AUTOSAR XML (schema 4-2-2)
package /STELLANTIS/EPT/ASWCs
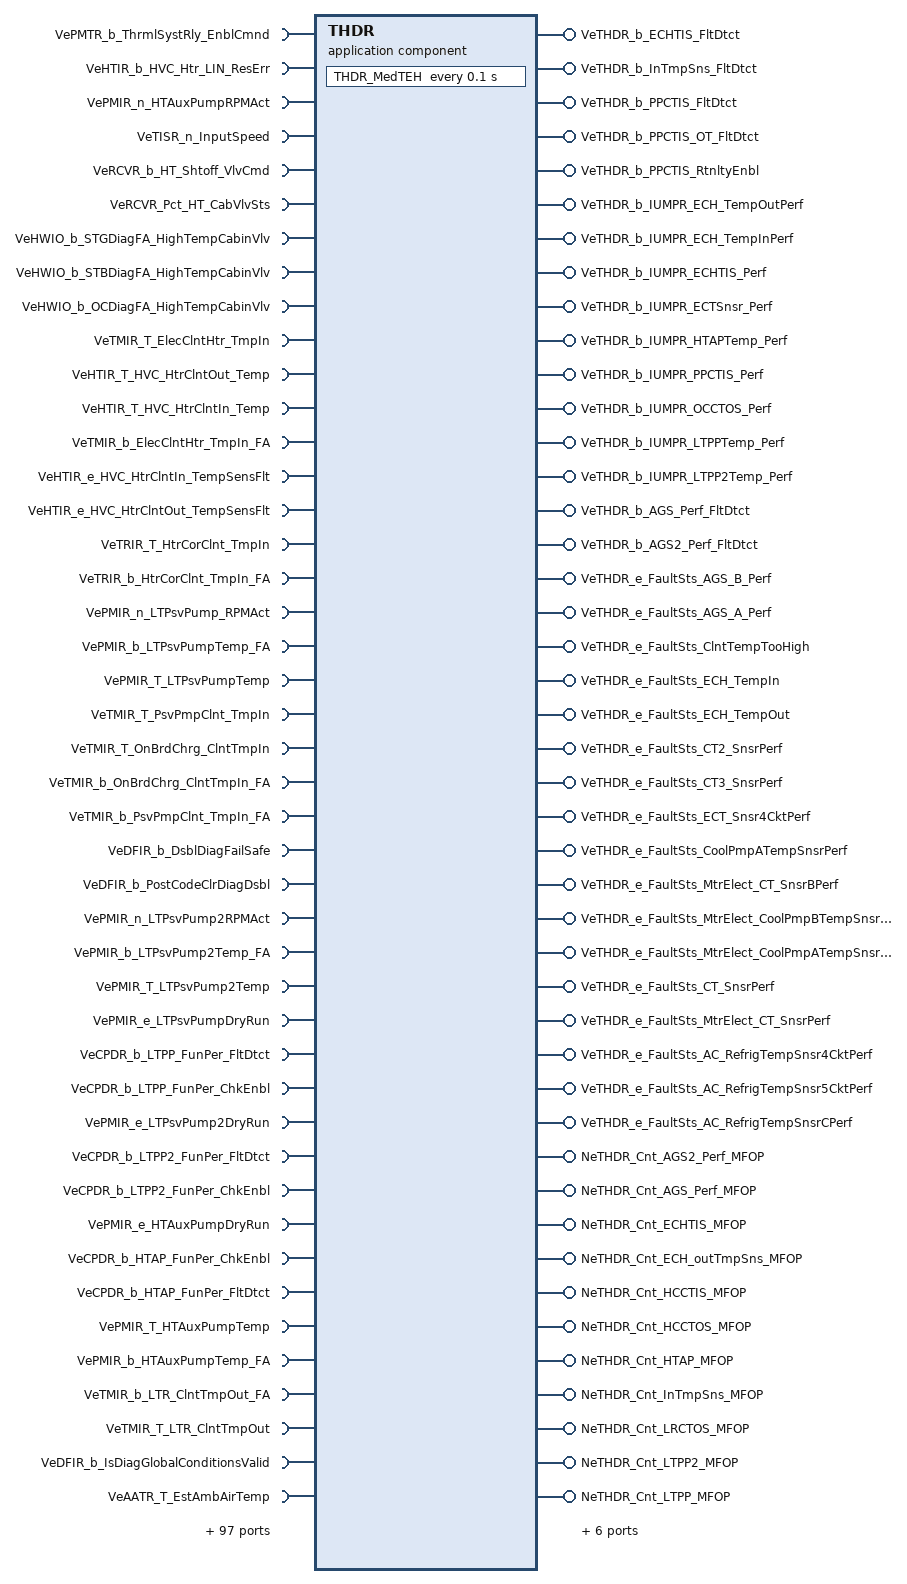
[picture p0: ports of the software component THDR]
  application sw component type THDR
    124 x require port:
      VePMTR_b_ThrmlSystRly_EnblCmnd: variation-point={short-label=vpVePMTR_b_ThrmlSystRly_EnblCmnd, sw-syscond=1}, nonqueued-receiver-com-spec{data-element=Value, init-value=0}, required-interface=VePMTR_b_ThrmlSystRly_EnblCmnd
      VeHTIR_b_HVC_Htr_LIN_ResErr: variation-point={short-label=vpVeHTIR_b_HVC_Htr_LIN_ResErr, sw-syscond=1}, nonqueued-receiver-com-spec{data-element=Value, init-value=0}, required-interface=VeHTIR_b_HVC_Htr_LIN_ResErr
      VePMIR_n_HTAuxPumpRPMAct: variation-point={short-label=vpVePMIR_n_HTAuxPumpRPMAct, sw-syscond=1}, nonqueued-receiver-com-spec{data-element=Value, init-value=0}, required-interface=VePMIR_n_HTAuxPumpRPMAct
      VeTISR_n_InputSpeed: variation-point={short-label=vpVeTISR_n_InputSpeed, sw-syscond=1}, nonqueued-receiver-com-spec{data-element=Value, init-value=0}, required-interface=VeTISR_n_InputSpeed
      VeRCVR_b_HT_Shtoff_VlvCmd: variation-point={short-label=vpVeRCVR_b_HT_Shtoff_VlvCmd, sw-syscond=1}, nonqueued-receiver-com-spec{data-element=Value, init-value=0}, required-interface=VeRCVR_b_HT_Shtoff_VlvCmd
      VeRCVR_Pct_HT_CabVlvSts: variation-point={short-label=vpVeRCVR_Pct_HT_CabVlvSts, sw-syscond=1}, nonqueued-receiver-com-spec{data-element=Value, init-value=0}, required-interface=VeRCVR_Pct_HT_CabVlvSts
      VeHWIO_b_STGDiagFA_HighTempCabinVlv: variation-point={short-label=vpVeHWIO_b_STGDiagFA_HighTempCabinVlv, sw-syscond=1}, nonqueued-receiver-com-spec{data-element=Value, init-value=0}, required-interface=VeHWIO_b_STGDiagFA_HighTempCabinVlv
      VeHWIO_b_STBDiagFA_HighTempCabinVlv: variation-point={short-label=vpVeHWIO_b_STBDiagFA_HighTempCabinVlv, sw-syscond=1}, nonqueued-receiver-com-spec{data-element=Value, init-value=0}, required-interface=VeHWIO_b_STBDiagFA_HighTempCabinVlv
      VeHWIO_b_OCDiagFA_HighTempCabinVlv: variation-point={short-label=vpVeHWIO_b_OCDiagFA_HighTempCabinVlv, sw-syscond=1}, nonqueued-receiver-com-spec{data-element=Value, init-value=0}, required-interface=VeHWIO_b_OCDiagFA_HighTempCabinVlv
      VeTMIR_T_ElecClntHtr_TmpIn: variation-point={short-label=vpVeTMIR_T_ElecClntHtr_TmpIn, sw-syscond=1}, nonqueued-receiver-com-spec{data-element=Value, init-value=0}, required-interface=VeTMIR_T_ElecClntHtr_TmpIn
      VeHTIR_T_HVC_HtrClntOut_Temp: variation-point={short-label=vpVeHTIR_T_HVC_HtrClntOut_Temp, sw-syscond=1}, nonqueued-receiver-com-spec{data-element=Value, init-value=0}, required-interface=VeHTIR_T_HVC_HtrClntOut_Temp
      VeHTIR_T_HVC_HtrClntIn_Temp: variation-point={short-label=vpVeHTIR_T_HVC_HtrClntIn_Temp, sw-syscond=1}, nonqueued-receiver-com-spec{data-element=Value, init-value=0}, required-interface=VeHTIR_T_HVC_HtrClntIn_Temp
      VeTMIR_b_ElecClntHtr_TmpIn_FA: variation-point={short-label=vpVeTMIR_b_ElecClntHtr_TmpIn_FA, sw-syscond=1}, nonqueued-receiver-com-spec{data-element=Value, init-value=0}, required-interface=VeTMIR_b_ElecClntHtr_TmpIn_FA
      VeHTIR_e_HVC_HtrClntIn_TempSensFlt: variation-point={short-label=vpVeHTIR_e_HVC_HtrClntIn_TempSensFlt, sw-syscond=1}, nonqueued-receiver-com-spec{data-element=Value, init-value=CeHTIR_e_Warning_False}, required-interface=VeHTIR_e_HVC_HtrClntIn_TempSensFlt
      VeHTIR_e_HVC_HtrClntOut_TempSensFlt: variation-point={short-label=vpVeHTIR_e_HVC_HtrClntOut_TempSensFlt, sw-syscond=1}, nonqueued-receiver-com-spec{data-element=Value, init-value=CeHTIR_e_Warning_False}, required-interface=VeHTIR_e_HVC_HtrClntOut_TempSensFlt
      VeTRIR_T_HtrCorClnt_TmpIn: variation-point={short-label=vpVeTRIR_T_HtrCorClnt_TmpIn, sw-syscond=1}, nonqueued-receiver-com-spec{data-element=Value, init-value=0}, required-interface=VeTRIR_T_HtrCorClnt_TmpIn
      VeTRIR_b_HtrCorClnt_TmpIn_FA: variation-point={short-label=vpVeTRIR_b_HtrCorClnt_TmpIn_FA, sw-syscond=1}, nonqueued-receiver-com-spec{data-element=Value, init-value=0}, required-interface=VeTRIR_b_HtrCorClnt_TmpIn_FA
      VePMIR_n_LTPsvPump_RPMAct: variation-point={short-label=vpVePMIR_n_LTPsvPump_RPMAct, sw-syscond=1}, nonqueued-receiver-com-spec{data-element=Value, init-value=0}, required-interface=VePMIR_n_LTPsvPump_RPMAct
      VePMIR_b_LTPsvPumpTemp_FA: variation-point={short-label=vpVePMIR_b_LTPsvPumpTemp_FA, sw-syscond=1}, nonqueued-receiver-com-spec{data-element=Value, init-value=0}, required-interface=VePMIR_b_LTPsvPumpTemp_FA
      VePMIR_T_LTPsvPumpTemp: variation-point={short-label=vpVePMIR_T_LTPsvPumpTemp, sw-syscond=1}, nonqueued-receiver-com-spec{data-element=Value, init-value=0}, required-interface=VePMIR_T_LTPsvPumpTemp
      VeTMIR_T_PsvPmpClnt_TmpIn: variation-point={short-label=vpVeTMIR_T_PsvPmpClnt_TmpIn, sw-syscond=1}, nonqueued-receiver-com-spec{data-element=Value, init-value=0}, required-interface=VeTMIR_T_PsvPmpClnt_TmpIn
      VeTMIR_T_OnBrdChrg_ClntTmpIn: variation-point={short-label=vpVeTMIR_T_OnBrdChrg_ClntTmpIn, sw-syscond=1}, nonqueued-receiver-com-spec{data-element=Value, init-value=0}, required-interface=VeTMIR_T_OnBrdChrg_ClntTmpIn
      VeTMIR_b_OnBrdChrg_ClntTmpIn_FA: variation-point={short-label=vpVeTMIR_b_OnBrdChrg_ClntTmpIn_FA, sw-syscond=1}, nonqueued-receiver-com-spec{data-element=Value, init-value=0}, required-interface=VeTMIR_b_OnBrdChrg_ClntTmpIn_FA
      VeTMIR_b_PsvPmpClnt_TmpIn_FA: variation-point={short-label=vpVeTMIR_b_PsvPmpClnt_TmpIn_FA, sw-syscond=1}, nonqueued-receiver-com-spec{data-element=Value, init-value=0}, required-interface=VeTMIR_b_PsvPmpClnt_TmpIn_FA
      VeDFIR_b_DsblDiagFailSafe: variation-point={short-label=vpVeDFIR_b_DsblDiagFailSafe, sw-syscond=1}, nonqueued-receiver-com-spec{data-element=Value, init-value=0}, required-interface=VeDFIR_b_DsblDiagFailSafe
      VeDFIR_b_PostCodeClrDiagDsbl: variation-point={short-label=vpVeDFIR_b_PostCodeClrDiagDsbl, sw-syscond=1}, nonqueued-receiver-com-spec{data-element=Value, init-value=0}, required-interface=VeDFIR_b_PostCodeClrDiagDsbl
      VePMIR_n_LTPsvPump2RPMAct: variation-point={short-label=vpVePMIR_n_LTPsvPump2RPMAct, sw-syscond=1}, nonqueued-receiver-com-spec{data-element=Value, init-value=0}, required-interface=VePMIR_n_LTPsvPump2RPMAct
      VePMIR_b_LTPsvPump2Temp_FA: variation-point={short-label=vpVePMIR_b_LTPsvPump2Temp_FA, sw-syscond=1}, nonqueued-receiver-com-spec{data-element=Value, init-value=0}, required-interface=VePMIR_b_LTPsvPump2Temp_FA
      VePMIR_T_LTPsvPump2Temp: variation-point={short-label=vpVePMIR_T_LTPsvPump2Temp, sw-syscond=1}, nonqueued-receiver-com-spec{data-element=Value, init-value=0}, required-interface=VePMIR_T_LTPsvPump2Temp
      VePMIR_e_LTPsvPumpDryRun: variation-point={short-label=vpVePMIR_e_LTPsvPumpDryRun, sw-syscond=1}, nonqueued-receiver-com-spec{data-element=Value, init-value=CePMPR_e_FTSNA_False}, required-interface=VePMIR_e_LTPsvPumpDryRun
      VeCPDR_b_LTPP_FunPer_FltDtct: variation-point={short-label=vpVeCPDR_b_LTPP_FunPer_FltDtct, sw-syscond=1}, nonqueued-receiver-com-spec{data-element=Value, init-value=0}, required-interface=VeCPDR_b_LTPP_FunPer_FltDtct
      VeCPDR_b_LTPP_FunPer_ChkEnbl: variation-point={short-label=vpVeCPDR_b_LTPP_FunPer_ChkEnbl, sw-syscond=1}, nonqueued-receiver-com-spec{data-element=Value, init-value=0}, required-interface=VeCPDR_b_LTPP_FunPer_ChkEnbl
      VePMIR_e_LTPsvPump2DryRun: variation-point={short-label=vpVePMIR_e_LTPsvPump2DryRun, sw-syscond=1}, nonqueued-receiver-com-spec{data-element=Value, init-value=CePMPR_e_FTSNA_False}, required-interface=VePMIR_e_LTPsvPump2DryRun
      VeCPDR_b_LTPP2_FunPer_FltDtct: variation-point={short-label=vpVeCPDR_b_LTPP2_FunPer_FltDtct, sw-syscond=1}, nonqueued-receiver-com-spec{data-element=Value, init-value=0}, required-interface=VeCPDR_b_LTPP2_FunPer_FltDtct
      VeCPDR_b_LTPP2_FunPer_ChkEnbl: variation-point={short-label=vpVeCPDR_b_LTPP2_FunPer_ChkEnbl, sw-syscond=1}, nonqueued-receiver-com-spec{data-element=Value, init-value=0}, required-interface=VeCPDR_b_LTPP2_FunPer_ChkEnbl
      VePMIR_e_HTAuxPumpDryRun: variation-point={short-label=vpVePMIR_e_HTAuxPumpDryRun, sw-syscond=1}, nonqueued-receiver-com-spec{data-element=Value, init-value=CePMPR_e_FTSNA_False}, required-interface=VePMIR_e_HTAuxPumpDryRun
      VeCPDR_b_HTAP_FunPer_ChkEnbl: variation-point={short-label=vpVeCPDR_b_HTAP_FunPer_ChkEnbl, sw-syscond=1}, nonqueued-receiver-com-spec{data-element=Value, init-value=0}, required-interface=VeCPDR_b_HTAP_FunPer_ChkEnbl
      VeCPDR_b_HTAP_FunPer_FltDtct: variation-point={short-label=vpVeCPDR_b_HTAP_FunPer_FltDtct, sw-syscond=1}, nonqueued-receiver-com-spec{data-element=Value, init-value=0}, required-interface=VeCPDR_b_HTAP_FunPer_FltDtct
      VePMIR_T_HTAuxPumpTemp: variation-point={short-label=vpVePMIR_T_HTAuxPumpTemp, sw-syscond=1}, nonqueued-receiver-com-spec{data-element=Value, init-value=0}, required-interface=VePMIR_T_HTAuxPumpTemp
      VePMIR_b_HTAuxPumpTemp_FA: variation-point={short-label=vpVePMIR_b_HTAuxPumpTemp_FA, sw-syscond=1}, nonqueued-receiver-com-spec{data-element=Value, init-value=0}, required-interface=VePMIR_b_HTAuxPumpTemp_FA
      VeTMIR_b_LTR_ClntTmpOut_FA: variation-point={short-label=vpVeTMIR_b_LTR_ClntTmpOut_FA, sw-syscond=1}, nonqueued-receiver-com-spec{data-element=Value, init-value=0}, required-interface=VeTMIR_b_LTR_ClntTmpOut_FA
      VeTMIR_T_LTR_ClntTmpOut: variation-point={short-label=vpVeTMIR_T_LTR_ClntTmpOut, sw-syscond=1}, nonqueued-receiver-com-spec{data-element=Value, init-value=0}, required-interface=VeTMIR_T_LTR_ClntTmpOut
      VeDFIR_b_IsDiagGlobalConditionsValid: variation-point={short-label=vpVeDFIR_b_IsDiagGlobalConditionsValid, sw-syscond=1}, nonqueued-receiver-com-spec{data-element=Value, init-value=0}, required-interface=VeDFIR_b_IsDiagGlobalConditionsValid
      VeAATR_T_EstAmbAirTemp: variation-point={short-label=vpVeAATR_T_EstAmbAirTemp, sw-syscond=1}, nonqueued-receiver-com-spec{data-element=Value, init-value=0}, required-interface=VeAATR_T_EstAmbAirTemp
      VePMDR_e_PMM_PowerMode: variation-point={short-label=vpVePMDR_e_PMM_PowerMode, sw-syscond=1}, nonqueued-receiver-com-spec{data-element=Value, init-value=CePMDR_e_PowerMode_Off}, required-interface=VePMDR_e_PMM_PowerMode
      VeTAIR_Pct_HTL_BypsVlv_ActlPstn: variation-point={short-label=vpVeTAIR_Pct_HTL_BypsVlv_ActlPstn, sw-syscond=1}, nonqueued-receiver-com-spec{data-element=Value, init-value=0}, required-interface=VeTAIR_Pct_HTL_BypsVlv_ActlPstn
      VeTAIR_e_AGS_CalibrationSts: variation-point={short-label=vpVeTAIR_e_AGS_CalibrationSts, sw-syscond=1}, nonqueued-receiver-com-spec{data-element=Value, init-value=CeTAIR_e_AGS_NotCalibrated}, required-interface=VeTAIR_e_AGS_CalibrationSts
      VeFSCR_b_AGS_CalAtmptThrshold: variation-point={short-label=vpVeFSCR_b_AGS_CalAtmptThrshold, sw-syscond=1}, nonqueued-receiver-com-spec{data-element=Value, init-value=0}, required-interface=VeFSCR_b_AGS_CalAtmptThrshold
      VeFSCR_e_AGS_PosReq: variation-point={short-label=vpVeFSCR_e_AGS_PosReq, sw-syscond=1}, nonqueued-receiver-com-spec{data-element=Value, init-value=CeFSCR_e_Open100}, required-interface=VeFSCR_e_AGS_PosReq
      VeTAIR_e_AGS_CurrPos: variation-point={short-label=vpVeTAIR_e_AGS_CurrPos, sw-syscond=1}, nonqueued-receiver-com-spec{data-element=Value, init-value=CeFSCR_e_Open100}, required-interface=VeTAIR_e_AGS_CurrPos
      VeTAIR_b_AGS_CurrPosFA: variation-point={short-label=vpVeTAIR_b_AGS_CurrPosFA, sw-syscond=1}, nonqueued-receiver-com-spec{data-element=Value, init-value=0}, required-interface=VeTAIR_b_AGS_CurrPosFA
      VePMIR_I_HTAuxPumpCurrent: variation-point={short-label=vpVePMIR_I_HTAuxPumpCurrent, sw-syscond=1}, nonqueued-receiver-com-spec{data-element=Value, init-value=0}, required-interface=VePMIR_I_HTAuxPumpCurrent
      VeDMAB_y_StatusByte_LIN2_BusOff: nonqueued-receiver-com-spec{data-element=Value, init-value=0}, required-interface=VeDMAB_y_StatusByte_LIN2_BusOff
      VeDMAB_y_StatusByte_LostComm_AGS_B: nonqueued-receiver-com-spec{data-element=Value, init-value=0}, required-interface=VeDMAB_y_StatusByte_LostComm_AGS_B
      VeDMAB_y_StatusByte_LIN3_BusOff: nonqueued-receiver-com-spec{data-element=Value, init-value=0}, required-interface=VeDMAB_y_StatusByte_LIN3_BusOff
      VeDMAB_y_StatusByte_LostComm_AGS_A: nonqueued-receiver-com-spec{data-element=Value, init-value=0}, required-interface=VeDMAB_y_StatusByte_LostComm_AGS_A
      VeDMAB_y_StatusByte_ThrmlRlyCtrlCkt: nonqueued-receiver-com-spec{data-element=Value, init-value=0}, required-interface=VeDMAB_y_StatusByte_ThrmlRlyCtrlCkt
      VeDMAB_y_StatusByte_CoolPmpACtrlCktPerf: nonqueued-receiver-com-spec{data-element=Value, init-value=0}, required-interface=VeDMAB_y_StatusByte_CoolPmpACtrlCktPerf
      VeDMAB_y_StatusByte_CoolPmpATempSnsrPerf: nonqueued-receiver-com-spec{data-element=Value, init-value=0}, required-interface=VeDMAB_y_StatusByte_CoolPmpATempSnsrPerf
      VeDMAB_y_StatusByte_ECH_TempIn: nonqueued-receiver-com-spec{data-element=Value, init-value=0}, required-interface=VeDMAB_y_StatusByte_ECH_TempIn
      VeDMAB_y_StatusByte_ECH_TempOut: nonqueued-receiver-com-spec{data-element=Value, init-value=0}, required-interface=VeDMAB_y_StatusByte_ECH_TempOut
      VeDMAB_y_StatusByte_LIN1_BusOff: nonqueued-receiver-com-spec{data-element=Value, init-value=0}, required-interface=VeDMAB_y_StatusByte_LIN1_BusOff
      VeDMAB_y_StatusByte_CT2_SnsrCktHi: nonqueued-receiver-com-spec{data-element=Value, init-value=0}, required-interface=VeDMAB_y_StatusByte_CT2_SnsrCktHi
      VeDMAB_y_StatusByte_CT2_SnsrCktLo: nonqueued-receiver-com-spec{data-element=Value, init-value=0}, required-interface=VeDMAB_y_StatusByte_CT2_SnsrCktLo
      VeDMAB_y_StatusByte_CT2_SnsrPerf: nonqueued-receiver-com-spec{data-element=Value, init-value=0}, required-interface=VeDMAB_y_StatusByte_CT2_SnsrPerf
      VeDMAB_y_StatusByte_LostCommCoolHtrA: nonqueued-receiver-com-spec{data-element=Value, init-value=0}, required-interface=VeDMAB_y_StatusByte_LostCommCoolHtrA
      VeDMAB_y_StatusByte_CT3_SnsrPerf: nonqueued-receiver-com-spec{data-element=Value, init-value=0}, required-interface=VeDMAB_y_StatusByte_CT3_SnsrPerf
      VeDMAB_y_StatusByte_LostCommCoolPmpA: nonqueued-receiver-com-spec{data-element=Value, init-value=0}, required-interface=VeDMAB_y_StatusByte_LostCommCoolPmpA
      VeDMAB_y_StatusByte_CT_SnsrPerf: nonqueued-receiver-com-spec{data-element=Value, init-value=0}, required-interface=VeDMAB_y_StatusByte_CT_SnsrPerf
      VeDMAB_y_StatusByte_MtrElect_CooPumBOvrSpd: nonqueued-receiver-com-spec{data-element=Value, init-value=0}, required-interface=VeDMAB_y_StatusByte_MtrElect_CooPumBOvrSpd
      VeDMAB_y_StatusByte_MtrElect_CoolPmpATempSnsrPerf: nonqueued-receiver-com-spec{data-element=Value, init-value=0}, required-interface=VeDMAB_y_StatusByte_MtrElect_CoolPmpATempSnsrPerf
      VeDMAB_y_StatusByte_MtrElect_CoolPmpBTempSnsrPerf: nonqueued-receiver-com-spec{data-element=Value, init-value=0}, required-interface=VeDMAB_y_StatusByte_MtrElect_CoolPmpBTempSnsrPerf
      VeDMAB_y_StatusByte_MtrElect_CoolPumAOvrSpd: nonqueued-receiver-com-spec{data-element=Value, init-value=0}, required-interface=VeDMAB_y_StatusByte_MtrElect_CoolPumAOvrSpd
      VeDMAB_y_StatusByte_MtrElect_CoolPumBCtrlPerf: nonqueued-receiver-com-spec{data-element=Value, init-value=0}, required-interface=VeDMAB_y_StatusByte_MtrElect_CoolPumBCtrlPerf
      VeDMAB_y_StatusByte_PwrElecPmpPerf: nonqueued-receiver-com-spec{data-element=Value, init-value=0}, required-interface=VeDMAB_y_StatusByte_PwrElecPmpPerf
      VeDMAB_y_StatusByte_CommBusOff: nonqueued-receiver-com-spec{data-element=Value, init-value=0}, required-interface=VeDMAB_y_StatusByte_CommBusOff
      VeDMAB_y_StatusByte_LosCommBECM_A: nonqueued-receiver-com-spec{data-element=Value, init-value=0}, required-interface=VeDMAB_y_StatusByte_LosCommBECM_A
      VeDMAB_y_StatusByte_MtrElect_CT_SnsrPerf: nonqueued-receiver-com-spec{data-element=Value, init-value=0}, required-interface=VeDMAB_y_StatusByte_MtrElect_CT_SnsrPerf
      VeDMAB_y_StatusByte_CT3_SnsrCktHi: nonqueued-receiver-com-spec{data-element=Value, init-value=0}, required-interface=VeDMAB_y_StatusByte_CT3_SnsrCktHi
      VeDMAB_y_StatusByte_CT3_SnsrCktLo: nonqueued-receiver-com-spec{data-element=Value, init-value=0}, required-interface=VeDMAB_y_StatusByte_CT3_SnsrCktLo
      VeDMAB_y_StatusByte_CT_SnsrCktHi: nonqueued-receiver-com-spec{data-element=Value, init-value=0}, required-interface=VeDMAB_y_StatusByte_CT_SnsrCktHi
      VeDMAB_y_StatusByte_CT_SnsrCktLo: nonqueued-receiver-com-spec{data-element=Value, init-value=0}, required-interface=VeDMAB_y_StatusByte_CT_SnsrCktLo
      VeDMAB_y_StatusByte_MtrElect_CT2_SnsrBCktHi: nonqueued-receiver-com-spec{data-element=Value, init-value=0}, required-interface=VeDMAB_y_StatusByte_MtrElect_CT2_SnsrBCktHi
      VeDMAB_y_StatusByte_MtrElect_CT2_SnsrBCktLo: nonqueued-receiver-com-spec{data-element=Value, init-value=0}, required-interface=VeDMAB_y_StatusByte_MtrElect_CT2_SnsrBCktLo
      VeDMAB_y_StatusByte_MtrElect_CT_SnsrCktHi: nonqueued-receiver-com-spec{data-element=Value, init-value=0}, required-interface=VeDMAB_y_StatusByte_MtrElect_CT_SnsrCktHi
      VeDMAB_y_StatusByte_MtrElect_CT_SnsrCktLo: nonqueued-receiver-com-spec{data-element=Value, init-value=0}, required-interface=VeDMAB_y_StatusByte_MtrElect_CT_SnsrCktLo
      VeDMAB_y_StatusByte_CoolantVlvA_Perf: nonqueued-receiver-com-spec{data-element=Value, init-value=0}, required-interface=VeDMAB_y_StatusByte_CoolantVlvA_Perf
      VeDMAB_y_StatusByte_ECT_Snsr4CktPerf: nonqueued-receiver-com-spec{data-element=Value, init-value=0}, required-interface=VeDMAB_y_StatusByte_ECT_Snsr4CktPerf
      VeDMAB_y_StatusByte_LostCommMtrElectCoolPmpA: nonqueued-receiver-com-spec{data-element=Value, init-value=0}, required-interface=VeDMAB_y_StatusByte_LostCommMtrElectCoolPmpA
      VeDMAB_y_StatusByte_LostCommMtrElectCoolPmpB: nonqueued-receiver-com-spec{data-element=Value, init-value=0}, required-interface=VeDMAB_y_StatusByte_LostCommMtrElectCoolPmpB
      VeDMAB_y_StatusByte_MtrElect_CT_SnsrBPerf: nonqueued-receiver-com-spec{data-element=Value, init-value=0}, required-interface=VeDMAB_y_StatusByte_MtrElect_CT_SnsrBPerf
      VeDMAB_y_StatusByte_HB_PSC_CtrlValBCktPerf: nonqueued-receiver-com-spec{data-element=Value, init-value=0}, required-interface=VeDMAB_y_StatusByte_HB_PSC_CtrlValBCktPerf
      VeDMAB_y_StatusByte_LostCommHB_PSCCooCtrlVlvB: nonqueued-receiver-com-spec{data-element=Value, init-value=0}, required-interface=VeDMAB_y_StatusByte_LostCommHB_PSCCooCtrlVlvB
      VeTAIR_b_OEXV_RefTemp_FA: variation-point={short-label=vpVeTAIR_b_OEXV_RefTemp_FA, sw-syscond=1}, nonqueued-receiver-com-spec{data-element=Value, init-value=0}, required-interface=VeTAIR_b_OEXV_RefTemp_FA
      VeTAIR_b_OEXV_InTempSens_FA: variation-point={short-label=vpVeTAIR_b_OEXV_InTempSens_FA, sw-syscond=1}, nonqueued-receiver-com-spec{data-element=Value, init-value=0}, required-interface=VeTAIR_b_OEXV_InTempSens_FA
      VeTAIR_b_EEXV_RefTemp_FA: variation-point={short-label=vpVeTAIR_b_EEXV_RefTemp_FA, sw-syscond=1}, nonqueued-receiver-com-spec{data-element=Value, init-value=0}, required-interface=VeTAIR_b_EEXV_RefTemp_FA
      VeTAIR_T_OEXV_RefTemp: variation-point={short-label=vpVeTAIR_T_OEXV_RefTemp, sw-syscond=1}, nonqueued-receiver-com-spec{data-element=Value, init-value=0}, required-interface=VeTAIR_T_OEXV_RefTemp
      VeTAIR_T_OEXV_InTempSens: variation-point={short-label=vpVeTAIR_T_OEXV_InTempSens, sw-syscond=1}, nonqueued-receiver-com-spec{data-element=Value, init-value=0}, required-interface=VeTAIR_T_OEXV_InTempSens
      VeTAIR_T_EEXV_RefTemp: variation-point={short-label=vpVeTAIR_T_EEXV_RefTemp, sw-syscond=1}, nonqueued-receiver-com-spec{data-element=Value, init-value=0}, required-interface=VeTAIR_T_EEXV_RefTemp
      VeTAIR_e_CompStat: variation-point={short-label=vpVeTAIR_e_CompStat, sw-syscond=1}, nonqueued-receiver-com-spec{data-element=Value, init-value=CeTAIR_e_NormalOp}, required-interface=VeTAIR_e_CompStat
      VeTAIR_b_WinshldDfrst: variation-point={short-label=vpVeTAIR_b_WinshldDfrst, sw-syscond=1}, nonqueued-receiver-com-spec{data-element=Value, init-value=0}, required-interface=VeTAIR_b_WinshldDfrst
      VePLTR_t_HCPOffTime: variation-point={short-label=vpVePLTR_t_HCPOffTime, sw-syscond=1}, nonqueued-receiver-com-spec{data-element=Value, init-value=0}, required-interface=VePLTR_t_HCPOffTime
      VePLTR_b_HCPOffTimeFA: variation-point={short-label=vpVePLTR_b_HCPOffTimeFA, sw-syscond=1}, nonqueued-receiver-com-spec{data-element=Value, init-value=0}, required-interface=VePLTR_b_HCPOffTimeFA
      VeTAIR_n_CompSpdFdb: variation-point={short-label=vpVeTAIR_n_CompSpdFdb, sw-syscond=1}, nonqueued-receiver-com-spec{data-element=Value, init-value=0}, required-interface=VeTAIR_n_CompSpdFdb
      VeDMAB_y_StatusByte_EACPerf: nonqueued-receiver-com-spec{data-element=Value, init-value=0}, required-interface=VeDMAB_y_StatusByte_EACPerf
      VeDMAB_y_StatusByte_LostCommEAC: nonqueued-receiver-com-spec{data-element=Value, init-value=0}, required-interface=VeDMAB_y_StatusByte_LostCommEAC
      VeDMAB_y_StatusByte_AC_RefrigExpVlvAct_C_CntrlCktPerf: nonqueued-receiver-com-spec{data-element=Value, init-value=0}, required-interface=VeDMAB_y_StatusByte_AC_RefrigExpVlvAct_C_CntrlCktPerf
      VeDMAB_y_StatusByte_AC_RefrigTempSnsrCCkt: nonqueued-receiver-com-spec{data-element=Value, init-value=0}, required-interface=VeDMAB_y_StatusByte_AC_RefrigTempSnsrCCkt
      VeDMAB_y_StatusByte_LostCommACRefrigExpVlvActC: nonqueued-receiver-com-spec{data-element=Value, init-value=0}, required-interface=VeDMAB_y_StatusByte_LostCommACRefrigExpVlvActC
      VeDMAB_y_StatusByte_AC_RefrigTempSnsr5CktShotoBat: nonqueued-receiver-com-spec{data-element=Value, init-value=0}, required-interface=VeDMAB_y_StatusByte_AC_RefrigTempSnsr5CktShotoBat
      VeDMAB_y_StatusByte_AC_RefrigTempSnsr5CktShotoGro: nonqueued-receiver-com-spec{data-element=Value, init-value=0}, required-interface=VeDMAB_y_StatusByte_AC_RefrigTempSnsr5CktShotoGro
      VeDMAB_y_StatusByte_AC_RefrigExpVlvActD_CntrlCktPerf: nonqueued-receiver-com-spec{data-element=Value, init-value=0}, required-interface=VeDMAB_y_StatusByte_AC_RefrigExpVlvActD_CntrlCktPerf
      VeDMAB_y_StatusByte_AC_RefrigTempSnsrDCkt: nonqueued-receiver-com-spec{data-element=Value, init-value=0}, required-interface=VeDMAB_y_StatusByte_AC_RefrigTempSnsrDCkt
      VeDMAB_y_StatusByte_LostCommACRefrigExpVlvActD: nonqueued-receiver-com-spec{data-element=Value, init-value=0}, required-interface=VeDMAB_y_StatusByte_LostCommACRefrigExpVlvActD
      VeDMAB_y_StatusByte_AC_RefrigTempSnsr4CktPerf: nonqueued-receiver-com-spec{data-element=Value, init-value=0}, required-interface=VeDMAB_y_StatusByte_AC_RefrigTempSnsr4CktPerf
      VeDMAB_y_StatusByte_AC_RefrigTempSnsr5CktPerf: nonqueued-receiver-com-spec{data-element=Value, init-value=0}, required-interface=VeDMAB_y_StatusByte_AC_RefrigTempSnsr5CktPerf
      VeDMAB_y_StatusByte_AC_RefrigTempSnsrCPerf: nonqueued-receiver-com-spec{data-element=Value, init-value=0}, required-interface=VeDMAB_y_StatusByte_AC_RefrigTempSnsrCPerf
      VeDMAB_y_StatusByte_ClntTempTooHigh: nonqueued-receiver-com-spec{data-element=Value, init-value=0}, required-interface=VeDMAB_y_StatusByte_ClntTempTooHigh
      VeDMAB_y_StatusByte_AGS_A_Perf: nonqueued-receiver-com-spec{data-element=Value, init-value=0}, required-interface=VeDMAB_y_StatusByte_AGS_A_Perf
      VeDMAB_y_StatusByte_AGS_B_Perf: nonqueued-receiver-com-spec{data-element=Value, init-value=0}, required-interface=VeDMAB_y_StatusByte_AGS_B_Perf
      VeTAIR_Pct_CPV2_PstnAct: variation-point={short-label=vpVeTAIR_Pct_CPV2_PstnAct, sw-syscond=1}, nonqueued-receiver-com-spec{data-element=Value, init-value=0}, required-interface=VeTAIR_Pct_CPV2_PstnAct
      VeTAIR_b_CPV2_PstnAct_FA: variation-point={short-label=vpVeTAIR_b_CPV2_PstnAct_FA, sw-syscond=1}, nonqueued-receiver-com-spec{data-element=Value, init-value=0}, required-interface=VeTAIR_b_CPV2_PstnAct_FA
      VeDMAB_y_StatusByte_LostComm_HybPropSysCoolCntrlVal_E: nonqueued-receiver-com-spec{data-element=Value, init-value=0}, required-interface=VeDMAB_y_StatusByte_LostComm_HybPropSysCoolCntrlVal_E
      VeDMAB_y_StatusByte_HybPropSysCoolCntrlVal_E_Perf: nonqueued-receiver-com-spec{data-element=Value, init-value=0}, required-interface=VeDMAB_y_StatusByte_HybPropSysCoolCntrlVal_E_Perf
    33 x provide port:
      VeTHDR_b_ECHTIS_FltDtct: nonqueued-sender-com-spec{data-element=Value, init-value=0}, provided-interface=VeTHDR_b_ECHTIS_FltDtct
      VeTHDR_b_InTmpSns_FltDtct: nonqueued-sender-com-spec{data-element=Value, init-value=0}, provided-interface=VeTHDR_b_InTmpSns_FltDtct
      VeTHDR_b_PPCTIS_FltDtct: nonqueued-sender-com-spec{data-element=Value, init-value=0}, provided-interface=VeTHDR_b_PPCTIS_FltDtct
      VeTHDR_b_PPCTIS_OT_FltDtct: nonqueued-sender-com-spec{data-element=Value, init-value=0}, provided-interface=VeTHDR_b_PPCTIS_OT_FltDtct
      VeTHDR_b_PPCTIS_RtnltyEnbl: nonqueued-sender-com-spec{data-element=Value, init-value=0}, provided-interface=VeTHDR_b_PPCTIS_RtnltyEnbl
      VeTHDR_b_IUMPR_ECH_TempOutPerf: nonqueued-sender-com-spec{data-element=Value, init-value=0}, provided-interface=VeTHDR_b_IUMPR_ECH_TempOutPerf
      VeTHDR_b_IUMPR_ECH_TempInPerf: nonqueued-sender-com-spec{data-element=Value, init-value=0}, provided-interface=VeTHDR_b_IUMPR_ECH_TempInPerf
      VeTHDR_b_IUMPR_ECHTIS_Perf: nonqueued-sender-com-spec{data-element=Value, init-value=0}, provided-interface=VeTHDR_b_IUMPR_ECHTIS_Perf
      VeTHDR_b_IUMPR_ECTSnsr_Perf: nonqueued-sender-com-spec{data-element=Value, init-value=0}, provided-interface=VeTHDR_b_IUMPR_ECTSnsr_Perf
      VeTHDR_b_IUMPR_HTAPTemp_Perf: nonqueued-sender-com-spec{data-element=Value, init-value=0}, provided-interface=VeTHDR_b_IUMPR_HTAPTemp_Perf
      VeTHDR_b_IUMPR_PPCTIS_Perf: nonqueued-sender-com-spec{data-element=Value, init-value=0}, provided-interface=VeTHDR_b_IUMPR_PPCTIS_Perf
      VeTHDR_b_IUMPR_OCCTOS_Perf: nonqueued-sender-com-spec{data-element=Value, init-value=0}, provided-interface=VeTHDR_b_IUMPR_OCCTOS_Perf
      VeTHDR_b_IUMPR_LTPPTemp_Perf: nonqueued-sender-com-spec{data-element=Value, init-value=0}, provided-interface=VeTHDR_b_IUMPR_LTPPTemp_Perf
      VeTHDR_b_IUMPR_LTPP2Temp_Perf: nonqueued-sender-com-spec{data-element=Value, init-value=0}, provided-interface=VeTHDR_b_IUMPR_LTPP2Temp_Perf
      VeTHDR_b_AGS_Perf_FltDtct: nonqueued-sender-com-spec{data-element=Value, init-value=0}, provided-interface=VeTHDR_b_AGS_Perf_FltDtct
      VeTHDR_b_AGS2_Perf_FltDtct: nonqueued-sender-com-spec{data-element=Value, init-value=0}, provided-interface=VeTHDR_b_AGS2_Perf_FltDtct
      VeTHDR_e_FaultSts_AGS_B_Perf: nonqueued-sender-com-spec{data-element=Value, init-value=CeDFIB_e_Init}, provided-interface=VeTHDR_e_FaultSts_AGS_B_Perf
      VeTHDR_e_FaultSts_AGS_A_Perf: nonqueued-sender-com-spec{data-element=Value, init-value=CeDFIB_e_Init}, provided-interface=VeTHDR_e_FaultSts_AGS_A_Perf
      VeTHDR_e_FaultSts_ClntTempTooHigh: nonqueued-sender-com-spec{data-element=Value, init-value=CeDFIB_e_Init}, provided-interface=VeTHDR_e_FaultSts_ClntTempTooHigh
      VeTHDR_e_FaultSts_ECH_TempIn: nonqueued-sender-com-spec{data-element=Value, init-value=CeDFIB_e_Init}, provided-interface=VeTHDR_e_FaultSts_ECH_TempIn
      VeTHDR_e_FaultSts_ECH_TempOut: nonqueued-sender-com-spec{data-element=Value, init-value=CeDFIB_e_Init}, provided-interface=VeTHDR_e_FaultSts_ECH_TempOut
      VeTHDR_e_FaultSts_CT2_SnsrPerf: nonqueued-sender-com-spec{data-element=Value, init-value=CeDFIB_e_Init}, provided-interface=VeTHDR_e_FaultSts_CT2_SnsrPerf
      VeTHDR_e_FaultSts_CT3_SnsrPerf: nonqueued-sender-com-spec{data-element=Value, init-value=CeDFIB_e_Init}, provided-interface=VeTHDR_e_FaultSts_CT3_SnsrPerf
      VeTHDR_e_FaultSts_ECT_Snsr4CktPerf: nonqueued-sender-com-spec{data-element=Value, init-value=CeDFIB_e_Init}, provided-interface=VeTHDR_e_FaultSts_ECT_Snsr4CktPerf
      VeTHDR_e_FaultSts_CoolPmpATempSnsrPerf: nonqueued-sender-com-spec{data-element=Value, init-value=CeDFIB_e_Init}, provided-interface=VeTHDR_e_FaultSts_CoolPmpATempSnsrPerf
      VeTHDR_e_FaultSts_MtrElect_CT_SnsrBPerf: nonqueued-sender-com-spec{data-element=Value, init-value=CeDFIB_e_Init}, provided-interface=VeTHDR_e_FaultSts_MtrElect_CT_SnsrBPerf
      VeTHDR_e_FaultSts_MtrElect_CoolPmpBTempSnsrPerf: nonqueued-sender-com-spec{data-element=Value, init-value=CeDFIB_e_Init}, provided-interface=VeTHDR_e_FaultSts_MtrElect_CoolPmpBTempSnsrPerf
      VeTHDR_e_FaultSts_MtrElect_CoolPmpATempSnsrPerf: nonqueued-sender-com-spec{data-element=Value, init-value=CeDFIB_e_Init}, provided-interface=VeTHDR_e_FaultSts_MtrElect_CoolPmpATempSnsrPerf
      VeTHDR_e_FaultSts_CT_SnsrPerf: nonqueued-sender-com-spec{data-element=Value, init-value=CeDFIB_e_Init}, provided-interface=VeTHDR_e_FaultSts_CT_SnsrPerf
      VeTHDR_e_FaultSts_MtrElect_CT_SnsrPerf: nonqueued-sender-com-spec{data-element=Value, init-value=CeDFIB_e_Init}, provided-interface=VeTHDR_e_FaultSts_MtrElect_CT_SnsrPerf
      VeTHDR_e_FaultSts_AC_RefrigTempSnsr4CktPerf: nonqueued-sender-com-spec{data-element=Value, init-value=CeDFIB_e_Init}, provided-interface=VeTHDR_e_FaultSts_AC_RefrigTempSnsr4CktPerf
      VeTHDR_e_FaultSts_AC_RefrigTempSnsr5CktPerf: nonqueued-sender-com-spec{data-element=Value, init-value=CeDFIB_e_Init}, provided-interface=VeTHDR_e_FaultSts_AC_RefrigTempSnsr5CktPerf
      VeTHDR_e_FaultSts_AC_RefrigTempSnsrCPerf: nonqueued-sender-com-spec{data-element=Value, init-value=CeDFIB_e_Init}, provided-interface=VeTHDR_e_FaultSts_AC_RefrigTempSnsrCPerf
    17 x require port:
      NeTHDR_Cnt_AGS2_Perf_MFOP_Rx: nv-require-com-spec{init-value=0, variable=NeTHDR_Cnt_AGS2_Perf_MFOP}, required-interface=NeTHDR_Cnt_AGS2_Perf_MFOP
      NeTHDR_Cnt_AGS_Perf_MFOP_Rx: nv-require-com-spec{init-value=0, variable=NeTHDR_Cnt_AGS_Perf_MFOP}, required-interface=NeTHDR_Cnt_AGS_Perf_MFOP
      NeTHDR_Cnt_ECHTIS_MFOP_Rx: nv-require-com-spec{init-value=0, variable=NeTHDR_Cnt_ECHTIS_MFOP}, required-interface=NeTHDR_Cnt_ECHTIS_MFOP
      NeTHDR_Cnt_ECH_outTmpSns_MFOP_Rx: nv-require-com-spec{init-value=0, variable=NeTHDR_Cnt_ECH_outTmpSns_MFOP}, required-interface=NeTHDR_Cnt_ECH_outTmpSns_MFOP
      NeTHDR_Cnt_HCCTIS_MFOP_Rx: nv-require-com-spec{init-value=0, variable=NeTHDR_Cnt_HCCTIS_MFOP}, required-interface=NeTHDR_Cnt_HCCTIS_MFOP
      NeTHDR_Cnt_HCCTOS_MFOP_Rx: nv-require-com-spec{init-value=0, variable=NeTHDR_Cnt_HCCTOS_MFOP}, required-interface=NeTHDR_Cnt_HCCTOS_MFOP
      NeTHDR_Cnt_HTAP_MFOP_Rx: nv-require-com-spec{init-value=0, variable=NeTHDR_Cnt_HTAP_MFOP}, required-interface=NeTHDR_Cnt_HTAP_MFOP
      NeTHDR_Cnt_InTmpSns_MFOP_Rx: nv-require-com-spec{init-value=0, variable=NeTHDR_Cnt_InTmpSns_MFOP}, required-interface=NeTHDR_Cnt_InTmpSns_MFOP
      NeTHDR_Cnt_LRCTOS_MFOP_Rx: nv-require-com-spec{init-value=0, variable=NeTHDR_Cnt_LRCTOS_MFOP}, required-interface=NeTHDR_Cnt_LRCTOS_MFOP
      NeTHDR_Cnt_LTPP2_MFOP_Rx: nv-require-com-spec{init-value=0, variable=NeTHDR_Cnt_LTPP2_MFOP}, required-interface=NeTHDR_Cnt_LTPP2_MFOP
      NeTHDR_Cnt_LTPP_MFOP_Rx: nv-require-com-spec{init-value=0, variable=NeTHDR_Cnt_LTPP_MFOP}, required-interface=NeTHDR_Cnt_LTPP_MFOP
      NeTHDR_Cnt_OOCTOS_MFOP_Rx: nv-require-com-spec{init-value=0, variable=NeTHDR_Cnt_OOCTOS_MFOP}, required-interface=NeTHDR_Cnt_OOCTOS_MFOP
      NeTHDR_Cnt_PPCTIS_MFOP_Rx: nv-require-com-spec{init-value=0, variable=NeTHDR_Cnt_PPCTIS_MFOP}, required-interface=NeTHDR_Cnt_PPCTIS_MFOP
      NeTHDR_Cnt_PPCTIS_OT_MSOP_Rx: nv-require-com-spec{init-value=0, variable=NeTHDR_Cnt_PPCTIS_OT_MSOP}, required-interface=NeTHDR_Cnt_PPCTIS_OT_MSOP
      NeTHDR_Cnt_OEXV_Out_MFOP_Rx: nv-require-com-spec{init-value=0, variable=NeTHDR_Cnt_OEXV_Out_MFOP}, required-interface=NeTHDR_Cnt_OEXV_Out_MFOP
      NeTHDR_Cnt_OEXV_In_MFOP_Rx: nv-require-com-spec{init-value=0, variable=NeTHDR_Cnt_OEXV_In_MFOP}, required-interface=NeTHDR_Cnt_OEXV_In_MFOP
      NeTHDR_Cnt_EEXV_Out_MFOP_Rx: nv-require-com-spec{init-value=0, variable=NeTHDR_Cnt_EEXV_Out_MFOP}, required-interface=NeTHDR_Cnt_EEXV_Out_MFOP
    17 x provide port:
      NeTHDR_Cnt_AGS2_Perf_MFOP: nv-provide-com-spec{ram-block-init-value=0, variable=NeTHDR_Cnt_AGS2_Perf_MFOP}, provided-interface=NeTHDR_Cnt_AGS2_Perf_MFOP
      NeTHDR_Cnt_AGS_Perf_MFOP: nv-provide-com-spec{ram-block-init-value=0, variable=NeTHDR_Cnt_AGS_Perf_MFOP}, provided-interface=NeTHDR_Cnt_AGS_Perf_MFOP
      NeTHDR_Cnt_ECHTIS_MFOP: nv-provide-com-spec{ram-block-init-value=0, variable=NeTHDR_Cnt_ECHTIS_MFOP}, provided-interface=NeTHDR_Cnt_ECHTIS_MFOP
      NeTHDR_Cnt_ECH_outTmpSns_MFOP: nv-provide-com-spec{ram-block-init-value=0, variable=NeTHDR_Cnt_ECH_outTmpSns_MFOP}, provided-interface=NeTHDR_Cnt_ECH_outTmpSns_MFOP
      NeTHDR_Cnt_HCCTIS_MFOP: nv-provide-com-spec{ram-block-init-value=0, variable=NeTHDR_Cnt_HCCTIS_MFOP}, provided-interface=NeTHDR_Cnt_HCCTIS_MFOP
      NeTHDR_Cnt_HCCTOS_MFOP: nv-provide-com-spec{ram-block-init-value=0, variable=NeTHDR_Cnt_HCCTOS_MFOP}, provided-interface=NeTHDR_Cnt_HCCTOS_MFOP
      NeTHDR_Cnt_HTAP_MFOP: nv-provide-com-spec{ram-block-init-value=0, variable=NeTHDR_Cnt_HTAP_MFOP}, provided-interface=NeTHDR_Cnt_HTAP_MFOP
      NeTHDR_Cnt_InTmpSns_MFOP: nv-provide-com-spec{ram-block-init-value=0, variable=NeTHDR_Cnt_InTmpSns_MFOP}, provided-interface=NeTHDR_Cnt_InTmpSns_MFOP
      NeTHDR_Cnt_LRCTOS_MFOP: nv-provide-com-spec{ram-block-init-value=0, variable=NeTHDR_Cnt_LRCTOS_MFOP}, provided-interface=NeTHDR_Cnt_LRCTOS_MFOP
      NeTHDR_Cnt_LTPP2_MFOP: nv-provide-com-spec{ram-block-init-value=0, variable=NeTHDR_Cnt_LTPP2_MFOP}, provided-interface=NeTHDR_Cnt_LTPP2_MFOP
      NeTHDR_Cnt_LTPP_MFOP: nv-provide-com-spec{ram-block-init-value=0, variable=NeTHDR_Cnt_LTPP_MFOP}, provided-interface=NeTHDR_Cnt_LTPP_MFOP
      NeTHDR_Cnt_OOCTOS_MFOP: nv-provide-com-spec{ram-block-init-value=0, variable=NeTHDR_Cnt_OOCTOS_MFOP}, provided-interface=NeTHDR_Cnt_OOCTOS_MFOP
      NeTHDR_Cnt_PPCTIS_MFOP: nv-provide-com-spec{ram-block-init-value=0, variable=NeTHDR_Cnt_PPCTIS_MFOP}, provided-interface=NeTHDR_Cnt_PPCTIS_MFOP
      NeTHDR_Cnt_PPCTIS_OT_MSOP: nv-provide-com-spec{ram-block-init-value=0, variable=NeTHDR_Cnt_PPCTIS_OT_MSOP}, provided-interface=NeTHDR_Cnt_PPCTIS_OT_MSOP
      NeTHDR_Cnt_OEXV_Out_MFOP: nv-provide-com-spec{ram-block-init-value=0, variable=NeTHDR_Cnt_OEXV_Out_MFOP}, provided-interface=NeTHDR_Cnt_OEXV_Out_MFOP
      NeTHDR_Cnt_OEXV_In_MFOP: nv-provide-com-spec{ram-block-init-value=0, variable=NeTHDR_Cnt_OEXV_In_MFOP}, provided-interface=NeTHDR_Cnt_OEXV_In_MFOP
      NeTHDR_Cnt_EEXV_Out_MFOP: nv-provide-com-spec{ram-block-init-value=0, variable=NeTHDR_Cnt_EEXV_Out_MFOP}, provided-interface=NeTHDR_Cnt_EEXV_Out_MFOP
    behavior IB_THDR: data-type-mapping=msADTtoIDTMapping, handle-termination-and-restart=NO-SUPPORT
      timing event Event_MedTEH: start-on-event=THDR_MedTEH, period=0.1
      init event Event_THDR_ac_Init: start-on-event=THDR_ac_Init
      init event Event_PwrOn: start-on-event=THDR_PwrOn
      init event Event_PwrOff: start-on-event=THDR_PwrOff
      4 x runnable:
        THDR_ac_Init
          data-send-points:
            17 x access:
              OUT_VeTHDR_e_FaultSts_AGS_B_Perf_Value: accessed-variable=VeTHDR_e_FaultSts_AGS_B_Perf.Value
              OUT_VeTHDR_e_FaultSts_AGS_A_Perf_Value: accessed-variable=VeTHDR_e_FaultSts_AGS_A_Perf.Value
              OUT_VeTHDR_e_FaultSts_ClntTempTooHigh_Value: accessed-variable=VeTHDR_e_FaultSts_ClntTempTooHigh.Value
              OUT_VeTHDR_e_FaultSts_ECH_TempIn_Value: accessed-variable=VeTHDR_e_FaultSts_ECH_TempIn.Value
              OUT_VeTHDR_e_FaultSts_ECH_TempOut_Value: accessed-variable=VeTHDR_e_FaultSts_ECH_TempOut.Value
              OUT_VeTHDR_e_FaultSts_CT2_SnsrPerf_Value: accessed-variable=VeTHDR_e_FaultSts_CT2_SnsrPerf.Value
              OUT_VeTHDR_e_FaultSts_CT3_SnsrPerf_Value: accessed-variable=VeTHDR_e_FaultSts_CT3_SnsrPerf.Value
              OUT_VeTHDR_e_FaultSts_ECT_Snsr4CktPerf_Value: accessed-variable=VeTHDR_e_FaultSts_ECT_Snsr4CktPerf.Value
              OUT_VeTHDR_e_FaultSts_CoolPmpATempSnsrPerf_Value: accessed-variable=VeTHDR_e_FaultSts_CoolPmpATempSnsrPerf.Value
              OUT_VeTHDR_e_FaultSts_MtrElect_CT_SnsrBPerf_Value: accessed-variable=VeTHDR_e_FaultSts_MtrElect_CT_SnsrBPerf.Value
              OUT_VeTHDR_e_FaultSts_MtrElect_CoolPmpBTempSnsrPerf_Value: accessed-variable=VeTHDR_e_FaultSts_MtrElect_CoolPmpBTempSnsrPerf.Value
              OUT_VeTHDR_e_FaultSts_MtrElect_CoolPmpATempSnsrPerf_Value: accessed-variable=VeTHDR_e_FaultSts_MtrElect_CoolPmpATempSnsrPerf.Value
              OUT_VeTHDR_e_FaultSts_CT_SnsrPerf_Value: accessed-variable=VeTHDR_e_FaultSts_CT_SnsrPerf.Value
              OUT_VeTHDR_e_FaultSts_MtrElect_CT_SnsrPerf_Value: accessed-variable=VeTHDR_e_FaultSts_MtrElect_CT_SnsrPerf.Value
              OUT_VeTHDR_e_FaultSts_AC_RefrigTempSnsr4CktPerf_Value: accessed-variable=VeTHDR_e_FaultSts_AC_RefrigTempSnsr4CktPerf.Value
              OUT_VeTHDR_e_FaultSts_AC_RefrigTempSnsr5CktPerf_Value: accessed-variable=VeTHDR_e_FaultSts_AC_RefrigTempSnsr5CktPerf.Value
              OUT_VeTHDR_e_FaultSts_AC_RefrigTempSnsrCPerf_Value: accessed-variable=VeTHDR_e_FaultSts_AC_RefrigTempSnsrCPerf.Value
        THDR_MedTEH
          data-receive-point-by-arguments:
            124 x access:
              IN_VeAATR_T_EstAmbAirTemp_Value: accessed-variable=VeAATR_T_EstAmbAirTemp.Value, variation-point={short-label=vpIN_VeAATR_T_EstAmbAirTemp_Value, sw-syscond=1}
              IN_VeCPDR_b_HTAP_FunPer_ChkEnbl_Value: accessed-variable=VeCPDR_b_HTAP_FunPer_ChkEnbl.Value, variation-point={short-label=vpIN_VeCPDR_b_HTAP_FunPer_ChkEnbl_Value, sw-syscond=1}
              IN_VeCPDR_b_HTAP_FunPer_FltDtct_Value: accessed-variable=VeCPDR_b_HTAP_FunPer_FltDtct.Value, variation-point={short-label=vpIN_VeCPDR_b_HTAP_FunPer_FltDtct_Value, sw-syscond=1}
              IN_VeCPDR_b_LTPP2_FunPer_ChkEnbl_Value: accessed-variable=VeCPDR_b_LTPP2_FunPer_ChkEnbl.Value, variation-point={short-label=vpIN_VeCPDR_b_LTPP2_FunPer_ChkEnbl_Value, sw-syscond=1}
              IN_VeCPDR_b_LTPP2_FunPer_FltDtct_Value: accessed-variable=VeCPDR_b_LTPP2_FunPer_FltDtct.Value, variation-point={short-label=vpIN_VeCPDR_b_LTPP2_FunPer_FltDtct_Value, sw-syscond=1}
              IN_VeCPDR_b_LTPP_FunPer_ChkEnbl_Value: accessed-variable=VeCPDR_b_LTPP_FunPer_ChkEnbl.Value, variation-point={short-label=vpIN_VeCPDR_b_LTPP_FunPer_ChkEnbl_Value, sw-syscond=1}
              IN_VeCPDR_b_LTPP_FunPer_FltDtct_Value: accessed-variable=VeCPDR_b_LTPP_FunPer_FltDtct.Value, variation-point={short-label=vpIN_VeCPDR_b_LTPP_FunPer_FltDtct_Value, sw-syscond=1}
              IN_VeDFIR_b_DsblDiagFailSafe_Value: accessed-variable=VeDFIR_b_DsblDiagFailSafe.Value, variation-point={short-label=vpIN_VeDFIR_b_DsblDiagFailSafe_Value, sw-syscond=1}
              IN_VeDFIR_b_IsDiagGlobalConditionsValid_Value: accessed-variable=VeDFIR_b_IsDiagGlobalConditionsValid.Value, variation-point={short-label=vpIN_VeDFIR_b_IsDiagGlobalConditionsValid_Value, sw-syscond=1}
              IN_VeDFIR_b_PostCodeClrDiagDsbl_Value: accessed-variable=VeDFIR_b_PostCodeClrDiagDsbl.Value, variation-point={short-label=vpIN_VeDFIR_b_PostCodeClrDiagDsbl_Value, sw-syscond=1}
              IN_VeDMAB_y_StatusByte_AC_RefrigExpVlvActD_CntrlCktPerf_Value: accessed-variable=VeDMAB_y_StatusByte_AC_RefrigExpVlvActD_CntrlCktPerf.Value
              IN_VeDMAB_y_StatusByte_AC_RefrigExpVlvAct_C_CntrlCktPerf_Value: accessed-variable=VeDMAB_y_StatusByte_AC_RefrigExpVlvAct_C_CntrlCktPerf.Value
              IN_VeDMAB_y_StatusByte_AC_RefrigTempSnsr4CktPerf_Value: accessed-variable=VeDMAB_y_StatusByte_AC_RefrigTempSnsr4CktPerf.Value
              IN_VeDMAB_y_StatusByte_AC_RefrigTempSnsr5CktPerf_Value: accessed-variable=VeDMAB_y_StatusByte_AC_RefrigTempSnsr5CktPerf.Value
              IN_VeDMAB_y_StatusByte_AC_RefrigTempSnsr5CktShotoBat_Value: accessed-variable=VeDMAB_y_StatusByte_AC_RefrigTempSnsr5CktShotoBat.Value
              IN_VeDMAB_y_StatusByte_AC_RefrigTempSnsr5CktShotoGro_Value: accessed-variable=VeDMAB_y_StatusByte_AC_RefrigTempSnsr5CktShotoGro.Value
              IN_VeDMAB_y_StatusByte_AC_RefrigTempSnsrCCkt_Value: accessed-variable=VeDMAB_y_StatusByte_AC_RefrigTempSnsrCCkt.Value
              IN_VeDMAB_y_StatusByte_AC_RefrigTempSnsrCPerf_Value: accessed-variable=VeDMAB_y_StatusByte_AC_RefrigTempSnsrCPerf.Value
              IN_VeDMAB_y_StatusByte_AC_RefrigTempSnsrDCkt_Value: accessed-variable=VeDMAB_y_StatusByte_AC_RefrigTempSnsrDCkt.Value
              IN_VeDMAB_y_StatusByte_AGS_A_Perf_Value: accessed-variable=VeDMAB_y_StatusByte_AGS_A_Perf.Value
              IN_VeDMAB_y_StatusByte_AGS_B_Perf_Value: accessed-variable=VeDMAB_y_StatusByte_AGS_B_Perf.Value
              IN_VeDMAB_y_StatusByte_CT2_SnsrCktHi_Value: accessed-variable=VeDMAB_y_StatusByte_CT2_SnsrCktHi.Value
              IN_VeDMAB_y_StatusByte_CT2_SnsrCktLo_Value: accessed-variable=VeDMAB_y_StatusByte_CT2_SnsrCktLo.Value
              IN_VeDMAB_y_StatusByte_CT2_SnsrPerf_Value: accessed-variable=VeDMAB_y_StatusByte_CT2_SnsrPerf.Value
              IN_VeDMAB_y_StatusByte_CT3_SnsrCktHi_Value: accessed-variable=VeDMAB_y_StatusByte_CT3_SnsrCktHi.Value
              IN_VeDMAB_y_StatusByte_CT3_SnsrCktLo_Value: accessed-variable=VeDMAB_y_StatusByte_CT3_SnsrCktLo.Value
              IN_VeDMAB_y_StatusByte_CT3_SnsrPerf_Value: accessed-variable=VeDMAB_y_StatusByte_CT3_SnsrPerf.Value
              IN_VeDMAB_y_StatusByte_CT_SnsrCktHi_Value: accessed-variable=VeDMAB_y_StatusByte_CT_SnsrCktHi.Value
              IN_VeDMAB_y_StatusByte_CT_SnsrCktLo_Value: accessed-variable=VeDMAB_y_StatusByte_CT_SnsrCktLo.Value
              IN_VeDMAB_y_StatusByte_CT_SnsrPerf_Value: accessed-variable=VeDMAB_y_StatusByte_CT_SnsrPerf.Value
              IN_VeDMAB_y_StatusByte_ClntTempTooHigh_Value: accessed-variable=VeDMAB_y_StatusByte_ClntTempTooHigh.Value
              IN_VeDMAB_y_StatusByte_CommBusOff_Value: accessed-variable=VeDMAB_y_StatusByte_CommBusOff.Value
              IN_VeDMAB_y_StatusByte_CoolPmpACtrlCktPerf_Value: accessed-variable=VeDMAB_y_StatusByte_CoolPmpACtrlCktPerf.Value
              IN_VeDMAB_y_StatusByte_CoolPmpATempSnsrPerf_Value: accessed-variable=VeDMAB_y_StatusByte_CoolPmpATempSnsrPerf.Value
              IN_VeDMAB_y_StatusByte_CoolantVlvA_Perf_Value: accessed-variable=VeDMAB_y_StatusByte_CoolantVlvA_Perf.Value
              IN_VeDMAB_y_StatusByte_EACPerf_Value: accessed-variable=VeDMAB_y_StatusByte_EACPerf.Value
              IN_VeDMAB_y_StatusByte_ECH_TempIn_Value: accessed-variable=VeDMAB_y_StatusByte_ECH_TempIn.Value
              IN_VeDMAB_y_StatusByte_ECH_TempOut_Value: accessed-variable=VeDMAB_y_StatusByte_ECH_TempOut.Value
              IN_VeDMAB_y_StatusByte_ECT_Snsr4CktPerf_Value: accessed-variable=VeDMAB_y_StatusByte_ECT_Snsr4CktPerf.Value
              IN_VeDMAB_y_StatusByte_HB_PSC_CtrlValBCktPerf_Value: accessed-variable=VeDMAB_y_StatusByte_HB_PSC_CtrlValBCktPerf.Value
              IN_VeDMAB_y_StatusByte_HybPropSysCoolCntrlVal_E_Perf_Value: accessed-variable=VeDMAB_y_StatusByte_HybPropSysCoolCntrlVal_E_Perf.Value
              IN_VeDMAB_y_StatusByte_LIN{1..3}_BusOff_Value: accessed-variable=VeDMAB_y_StatusByte_LIN{1..3}_BusOff.Value
              IN_VeDMAB_y_StatusByte_LosCommBECM_A_Value: accessed-variable=VeDMAB_y_StatusByte_LosCommBECM_A.Value
              IN_VeDMAB_y_StatusByte_LostCommACRefrigExpVlvActC_Value: accessed-variable=VeDMAB_y_StatusByte_LostCommACRefrigExpVlvActC.Value
              IN_VeDMAB_y_StatusByte_LostCommACRefrigExpVlvActD_Value: accessed-variable=VeDMAB_y_StatusByte_LostCommACRefrigExpVlvActD.Value
              IN_VeDMAB_y_StatusByte_LostCommCoolHtrA_Value: accessed-variable=VeDMAB_y_StatusByte_LostCommCoolHtrA.Value
              IN_VeDMAB_y_StatusByte_LostCommCoolPmpA_Value: accessed-variable=VeDMAB_y_StatusByte_LostCommCoolPmpA.Value
              IN_VeDMAB_y_StatusByte_LostCommEAC_Value: accessed-variable=VeDMAB_y_StatusByte_LostCommEAC.Value
              IN_VeDMAB_y_StatusByte_LostCommHB_PSCCooCtrlVlvB_Value: accessed-variable=VeDMAB_y_StatusByte_LostCommHB_PSCCooCtrlVlvB.Value
              IN_VeDMAB_y_StatusByte_LostCommMtrElectCoolPmpA_Value: accessed-variable=VeDMAB_y_StatusByte_LostCommMtrElectCoolPmpA.Value
              IN_VeDMAB_y_StatusByte_LostCommMtrElectCoolPmpB_Value: accessed-variable=VeDMAB_y_StatusByte_LostCommMtrElectCoolPmpB.Value
              IN_VeDMAB_y_StatusByte_LostComm_AGS_A_Value: accessed-variable=VeDMAB_y_StatusByte_LostComm_AGS_A.Value
              IN_VeDMAB_y_StatusByte_LostComm_AGS_B_Value: accessed-variable=VeDMAB_y_StatusByte_LostComm_AGS_B.Value
              IN_VeDMAB_y_StatusByte_LostComm_HybPropSysCoolCntrlVal_E_Value: accessed-variable=VeDMAB_y_StatusByte_LostComm_HybPropSysCoolCntrlVal_E.Value
              IN_VeDMAB_y_StatusByte_MtrElect_CT2_SnsrBCktHi_Value: accessed-variable=VeDMAB_y_StatusByte_MtrElect_CT2_SnsrBCktHi.Value
              IN_VeDMAB_y_StatusByte_MtrElect_CT2_SnsrBCktLo_Value: accessed-variable=VeDMAB_y_StatusByte_MtrElect_CT2_SnsrBCktLo.Value
              IN_VeDMAB_y_StatusByte_MtrElect_CT_SnsrBPerf_Value: accessed-variable=VeDMAB_y_StatusByte_MtrElect_CT_SnsrBPerf.Value
              IN_VeDMAB_y_StatusByte_MtrElect_CT_SnsrCktHi_Value: accessed-variable=VeDMAB_y_StatusByte_MtrElect_CT_SnsrCktHi.Value
              IN_VeDMAB_y_StatusByte_MtrElect_CT_SnsrCktLo_Value: accessed-variable=VeDMAB_y_StatusByte_MtrElect_CT_SnsrCktLo.Value
              IN_VeDMAB_y_StatusByte_MtrElect_CT_SnsrPerf_Value: accessed-variable=VeDMAB_y_StatusByte_MtrElect_CT_SnsrPerf.Value
              IN_VeDMAB_y_StatusByte_MtrElect_CooPumBOvrSpd_Value: accessed-variable=VeDMAB_y_StatusByte_MtrElect_CooPumBOvrSpd.Value
              IN_VeDMAB_y_StatusByte_MtrElect_CoolPmpATempSnsrPerf_Value: accessed-variable=VeDMAB_y_StatusByte_MtrElect_CoolPmpATempSnsrPerf.Value
              IN_VeDMAB_y_StatusByte_MtrElect_CoolPmpBTempSnsrPerf_Value: accessed-variable=VeDMAB_y_StatusByte_MtrElect_CoolPmpBTempSnsrPerf.Value
              IN_VeDMAB_y_StatusByte_MtrElect_CoolPumAOvrSpd_Value: accessed-variable=VeDMAB_y_StatusByte_MtrElect_CoolPumAOvrSpd.Value
              IN_VeDMAB_y_StatusByte_MtrElect_CoolPumBCtrlPerf_Value: accessed-variable=VeDMAB_y_StatusByte_MtrElect_CoolPumBCtrlPerf.Value
              IN_VeDMAB_y_StatusByte_PwrElecPmpPerf_Value: accessed-variable=VeDMAB_y_StatusByte_PwrElecPmpPerf.Value
              IN_VeDMAB_y_StatusByte_ThrmlRlyCtrlCkt_Value: accessed-variable=VeDMAB_y_StatusByte_ThrmlRlyCtrlCkt.Value
              IN_VeFSCR_b_AGS_CalAtmptThrshold_Value: accessed-variable=VeFSCR_b_AGS_CalAtmptThrshold.Value, variation-point={short-label=vpIN_VeFSCR_b_AGS_CalAtmptThrshold_Value, sw-syscond=1}
              IN_VeFSCR_e_AGS_PosReq_Value: accessed-variable=VeFSCR_e_AGS_PosReq.Value, variation-point={short-label=vpIN_VeFSCR_e_AGS_PosReq_Value, sw-syscond=1}
              IN_VeHTIR_T_HVC_HtrClntIn_Temp_Value: accessed-variable=VeHTIR_T_HVC_HtrClntIn_Temp.Value, variation-point={short-label=vpIN_VeHTIR_T_HVC_HtrClntIn_Temp_Value, sw-syscond=1}
              IN_VeHTIR_T_HVC_HtrClntOut_Temp_Value: accessed-variable=VeHTIR_T_HVC_HtrClntOut_Temp.Value, variation-point={short-label=vpIN_VeHTIR_T_HVC_HtrClntOut_Temp_Value, sw-syscond=1}
              IN_VeHTIR_b_HVC_Htr_LIN_ResErr_Value: accessed-variable=VeHTIR_b_HVC_Htr_LIN_ResErr.Value, variation-point={short-label=vpIN_VeHTIR_b_HVC_Htr_LIN_ResErr_Value, sw-syscond=1}
              IN_VeHTIR_e_HVC_HtrClntIn_TempSensFlt_Value: accessed-variable=VeHTIR_e_HVC_HtrClntIn_TempSensFlt.Value, variation-point={short-label=vpIN_VeHTIR_e_HVC_HtrClntIn_TempSensFlt_Value, sw-syscond=1}
              IN_VeHTIR_e_HVC_HtrClntOut_TempSensFlt_Value: accessed-variable=VeHTIR_e_HVC_HtrClntOut_TempSensFlt.Value, variation-point={short-label=vpIN_VeHTIR_e_HVC_HtrClntOut_TempSensFlt_Value, sw-syscond=1}
              IN_VeHWIO_b_OCDiagFA_HighTempCabinVlv_Value: accessed-variable=VeHWIO_b_OCDiagFA_HighTempCabinVlv.Value, variation-point={short-label=vpIN_VeHWIO_b_OCDiagFA_HighTempCabinVlv_Value, sw-syscond=1}
              IN_VeHWIO_b_STBDiagFA_HighTempCabinVlv_Value: accessed-variable=VeHWIO_b_STBDiagFA_HighTempCabinVlv.Value, variation-point={short-label=vpIN_VeHWIO_b_STBDiagFA_HighTempCabinVlv_Value, sw-syscond=1}
              IN_VeHWIO_b_STGDiagFA_HighTempCabinVlv_Value: accessed-variable=VeHWIO_b_STGDiagFA_HighTempCabinVlv.Value, variation-point={short-label=vpIN_VeHWIO_b_STGDiagFA_HighTempCabinVlv_Value, sw-syscond=1}
              IN_VePLTR_b_HCPOffTimeFA_Value: accessed-variable=VePLTR_b_HCPOffTimeFA.Value, variation-point={short-label=vpIN_VePLTR_b_HCPOffTimeFA_Value, sw-syscond=1}
              IN_VePLTR_t_HCPOffTime_Value: accessed-variable=VePLTR_t_HCPOffTime.Value, variation-point={short-label=vpIN_VePLTR_t_HCPOffTime_Value, sw-syscond=1}
              IN_VePMDR_e_PMM_PowerMode_Value: accessed-variable=VePMDR_e_PMM_PowerMode.Value, variation-point={short-label=vpIN_VePMDR_e_PMM_PowerMode_Value, sw-syscond=1}
              IN_VePMIR_I_HTAuxPumpCurrent_Value: accessed-variable=VePMIR_I_HTAuxPumpCurrent.Value, variation-point={short-label=vpIN_VePMIR_I_HTAuxPumpCurrent_Value, sw-syscond=1}
              IN_VePMIR_T_HTAuxPumpTemp_Value: accessed-variable=VePMIR_T_HTAuxPumpTemp.Value, variation-point={short-label=vpIN_VePMIR_T_HTAuxPumpTemp_Value, sw-syscond=1}
              IN_VePMIR_T_LTPsvPump2Temp_Value: accessed-variable=VePMIR_T_LTPsvPump2Temp.Value, variation-point={short-label=vpIN_VePMIR_T_LTPsvPump2Temp_Value, sw-syscond=1}
              IN_VePMIR_T_LTPsvPumpTemp_Value: accessed-variable=VePMIR_T_LTPsvPumpTemp.Value, variation-point={short-label=vpIN_VePMIR_T_LTPsvPumpTemp_Value, sw-syscond=1}
              IN_VePMIR_b_HTAuxPumpTemp_FA_Value: accessed-variable=VePMIR_b_HTAuxPumpTemp_FA.Value, variation-point={short-label=vpIN_VePMIR_b_HTAuxPumpTemp_FA_Value, sw-syscond=1}
              IN_VePMIR_b_LTPsvPump2Temp_FA_Value: accessed-variable=VePMIR_b_LTPsvPump2Temp_FA.Value, variation-point={short-label=vpIN_VePMIR_b_LTPsvPump2Temp_FA_Value, sw-syscond=1}
              IN_VePMIR_b_LTPsvPumpTemp_FA_Value: accessed-variable=VePMIR_b_LTPsvPumpTemp_FA.Value, variation-point={short-label=vpIN_VePMIR_b_LTPsvPumpTemp_FA_Value, sw-syscond=1}
              IN_VePMIR_e_HTAuxPumpDryRun_Value: accessed-variable=VePMIR_e_HTAuxPumpDryRun.Value, variation-point={short-label=vpIN_VePMIR_e_HTAuxPumpDryRun_Value, sw-syscond=1}
              IN_VePMIR_e_LTPsvPump2DryRun_Value: accessed-variable=VePMIR_e_LTPsvPump2DryRun.Value, variation-point={short-label=vpIN_VePMIR_e_LTPsvPump2DryRun_Value, sw-syscond=1}
              IN_VePMIR_e_LTPsvPumpDryRun_Value: accessed-variable=VePMIR_e_LTPsvPumpDryRun.Value, variation-point={short-label=vpIN_VePMIR_e_LTPsvPumpDryRun_Value, sw-syscond=1}
              IN_VePMIR_n_HTAuxPumpRPMAct_Value: accessed-variable=VePMIR_n_HTAuxPumpRPMAct.Value, variation-point={short-label=vpIN_VePMIR_n_HTAuxPumpRPMAct_Value, sw-syscond=1}
              IN_VePMIR_n_LTPsvPump2RPMAct_Value: accessed-variable=VePMIR_n_LTPsvPump2RPMAct.Value, variation-point={short-label=vpIN_VePMIR_n_LTPsvPump2RPMAct_Value, sw-syscond=1}
              IN_VePMIR_n_LTPsvPump_RPMAct_Value: accessed-variable=VePMIR_n_LTPsvPump_RPMAct.Value, variation-point={short-label=vpIN_VePMIR_n_LTPsvPump_RPMAct_Value, sw-syscond=1}
              IN_VePMTR_b_ThrmlSystRly_EnblCmnd_Value: accessed-variable=VePMTR_b_ThrmlSystRly_EnblCmnd.Value, variation-point={short-label=vpIN_VePMTR_b_ThrmlSystRly_EnblCmnd_Value, sw-syscond=1}
              IN_VeRCVR_Pct_HT_CabVlvSts_Value: accessed-variable=VeRCVR_Pct_HT_CabVlvSts.Value, variation-point={short-label=vpIN_VeRCVR_Pct_HT_CabVlvSts_Value, sw-syscond=1}
              IN_VeRCVR_b_HT_Shtoff_VlvCmd_Value: accessed-variable=VeRCVR_b_HT_Shtoff_VlvCmd.Value, variation-point={short-label=vpIN_VeRCVR_b_HT_Shtoff_VlvCmd_Value, sw-syscond=1}
              IN_VeTAIR_Pct_CPV2_PstnAct_Value: accessed-variable=VeTAIR_Pct_CPV2_PstnAct.Value, variation-point={short-label=vpIN_VeTAIR_Pct_CPV2_PstnAct_Value, sw-syscond=1}
              IN_VeTAIR_Pct_HTL_BypsVlv_ActlPstn_Value: accessed-variable=VeTAIR_Pct_HTL_BypsVlv_ActlPstn.Value, variation-point={short-label=vpIN_VeTAIR_Pct_HTL_BypsVlv_ActlPstn_Value, sw-syscond=1}
              IN_VeTAIR_T_EEXV_RefTemp_Value: accessed-variable=VeTAIR_T_EEXV_RefTemp.Value, variation-point={short-label=vpIN_VeTAIR_T_EEXV_RefTemp_Value, sw-syscond=1}
              IN_VeTAIR_T_OEXV_InTempSens_Value: accessed-variable=VeTAIR_T_OEXV_InTempSens.Value, variation-point={short-label=vpIN_VeTAIR_T_OEXV_InTempSens_Value, sw-syscond=1}
              IN_VeTAIR_T_OEXV_RefTemp_Value: accessed-variable=VeTAIR_T_OEXV_RefTemp.Value, variation-point={short-label=vpIN_VeTAIR_T_OEXV_RefTemp_Value, sw-syscond=1}
              IN_VeTAIR_b_AGS_CurrPosFA_Value: accessed-variable=VeTAIR_b_AGS_CurrPosFA.Value, variation-point={short-label=vpIN_VeTAIR_b_AGS_CurrPosFA_Value, sw-syscond=1}
              IN_VeTAIR_b_CPV2_PstnAct_FA_Value: accessed-variable=VeTAIR_b_CPV2_PstnAct_FA.Value, variation-point={short-label=vpIN_VeTAIR_b_CPV2_PstnAct_FA_Value, sw-syscond=1}
              IN_VeTAIR_b_EEXV_RefTemp_FA_Value: accessed-variable=VeTAIR_b_EEXV_RefTemp_FA.Value, variation-point={short-label=vpIN_VeTAIR_b_EEXV_RefTemp_FA_Value, sw-syscond=1}
              IN_VeTAIR_b_OEXV_InTempSens_FA_Value: accessed-variable=VeTAIR_b_OEXV_InTempSens_FA.Value, variation-point={short-label=vpIN_VeTAIR_b_OEXV_InTempSens_FA_Value, sw-syscond=1}
              IN_VeTAIR_b_OEXV_RefTemp_FA_Value: accessed-variable=VeTAIR_b_OEXV_RefTemp_FA.Value, variation-point={short-label=vpIN_VeTAIR_b_OEXV_RefTemp_FA_Value, sw-syscond=1}
              IN_VeTAIR_b_WinshldDfrst_Value: accessed-variable=VeTAIR_b_WinshldDfrst.Value, variation-point={short-label=vpIN_VeTAIR_b_WinshldDfrst_Value, sw-syscond=1}
              IN_VeTAIR_e_AGS_CalibrationSts_Value: accessed-variable=VeTAIR_e_AGS_CalibrationSts.Value, variation-point={short-label=vpIN_VeTAIR_e_AGS_CalibrationSts_Value, sw-syscond=1}
              IN_VeTAIR_e_AGS_CurrPos_Value: accessed-variable=VeTAIR_e_AGS_CurrPos.Value, variation-point={short-label=vpIN_VeTAIR_e_AGS_CurrPos_Value, sw-syscond=1}
              IN_VeTAIR_e_CompStat_Value: accessed-variable=VeTAIR_e_CompStat.Value, variation-point={short-label=vpIN_VeTAIR_e_CompStat_Value, sw-syscond=1}
              IN_VeTAIR_n_CompSpdFdb_Value: accessed-variable=VeTAIR_n_CompSpdFdb.Value, variation-point={short-label=vpIN_VeTAIR_n_CompSpdFdb_Value, sw-syscond=1}
              IN_VeTISR_n_InputSpeed_Value: accessed-variable=VeTISR_n_InputSpeed.Value, variation-point={short-label=vpIN_VeTISR_n_InputSpeed_Value, sw-syscond=1}
              IN_VeTMIR_T_ElecClntHtr_TmpIn_Value: accessed-variable=VeTMIR_T_ElecClntHtr_TmpIn.Value, variation-point={short-label=vpIN_VeTMIR_T_ElecClntHtr_TmpIn_Value, sw-syscond=1}
              IN_VeTMIR_T_LTR_ClntTmpOut_Value: accessed-variable=VeTMIR_T_LTR_ClntTmpOut.Value, variation-point={short-label=vpIN_VeTMIR_T_LTR_ClntTmpOut_Value, sw-syscond=1}
              IN_VeTMIR_T_OnBrdChrg_ClntTmpIn_Value: accessed-variable=VeTMIR_T_OnBrdChrg_ClntTmpIn.Value, variation-point={short-label=vpIN_VeTMIR_T_OnBrdChrg_ClntTmpIn_Value, sw-syscond=1}
              IN_VeTMIR_T_PsvPmpClnt_TmpIn_Value: accessed-variable=VeTMIR_T_PsvPmpClnt_TmpIn.Value, variation-point={short-label=vpIN_VeTMIR_T_PsvPmpClnt_TmpIn_Value, sw-syscond=1}
              IN_VeTMIR_b_ElecClntHtr_TmpIn_FA_Value: accessed-variable=VeTMIR_b_ElecClntHtr_TmpIn_FA.Value, variation-point={short-label=vpIN_VeTMIR_b_ElecClntHtr_TmpIn_FA_Value, sw-syscond=1}
              IN_VeTMIR_b_LTR_ClntTmpOut_FA_Value: accessed-variable=VeTMIR_b_LTR_ClntTmpOut_FA.Value, variation-point={short-label=vpIN_VeTMIR_b_LTR_ClntTmpOut_FA_Value, sw-syscond=1}
              IN_VeTMIR_b_OnBrdChrg_ClntTmpIn_FA_Value: accessed-variable=VeTMIR_b_OnBrdChrg_ClntTmpIn_FA.Value, variation-point={short-label=vpIN_VeTMIR_b_OnBrdChrg_ClntTmpIn_FA_Value, sw-syscond=1}
              IN_VeTMIR_b_PsvPmpClnt_TmpIn_FA_Value: accessed-variable=VeTMIR_b_PsvPmpClnt_TmpIn_FA.Value, variation-point={short-label=vpIN_VeTMIR_b_PsvPmpClnt_TmpIn_FA_Value, sw-syscond=1}
              IN_VeTRIR_T_HtrCorClnt_TmpIn_Value: accessed-variable=VeTRIR_T_HtrCorClnt_TmpIn.Value, variation-point={short-label=vpIN_VeTRIR_T_HtrCorClnt_TmpIn_Value, sw-syscond=1}
              IN_VeTRIR_b_HtrCorClnt_TmpIn_FA_Value: accessed-variable=VeTRIR_b_HtrCorClnt_TmpIn_FA.Value, variation-point={short-label=vpIN_VeTRIR_b_HtrCorClnt_TmpIn_FA_Value, sw-syscond=1}
          data-send-points:
            33 x access:
              OUT_VeTHDR_b_ECHTIS_FltDtct_Value: accessed-variable=VeTHDR_b_ECHTIS_FltDtct.Value
              OUT_VeTHDR_b_InTmpSns_FltDtct_Value: accessed-variable=VeTHDR_b_InTmpSns_FltDtct.Value
              OUT_VeTHDR_b_PPCTIS_FltDtct_Value: accessed-variable=VeTHDR_b_PPCTIS_FltDtct.Value
              OUT_VeTHDR_b_PPCTIS_OT_FltDtct_Value: accessed-variable=VeTHDR_b_PPCTIS_OT_FltDtct.Value
              OUT_VeTHDR_b_PPCTIS_RtnltyEnbl_Value: accessed-variable=VeTHDR_b_PPCTIS_RtnltyEnbl.Value
              OUT_VeTHDR_b_AGS_Perf_FltDtct_Value: accessed-variable=VeTHDR_b_AGS_Perf_FltDtct.Value
              OUT_VeTHDR_b_AGS2_Perf_FltDtct_Value: accessed-variable=VeTHDR_b_AGS2_Perf_FltDtct.Value
              OUT_VeTHDR_b_IUMPR_ECH_TempOutPerf_Value: accessed-variable=VeTHDR_b_IUMPR_ECH_TempOutPerf.Value
              OUT_VeTHDR_b_IUMPR_ECH_TempInPerf_Value: accessed-variable=VeTHDR_b_IUMPR_ECH_TempInPerf.Value
              OUT_VeTHDR_b_IUMPR_ECHTIS_Perf_Value: accessed-variable=VeTHDR_b_IUMPR_ECHTIS_Perf.Value
              OUT_VeTHDR_b_IUMPR_ECTSnsr_Perf_Value: accessed-variable=VeTHDR_b_IUMPR_ECTSnsr_Perf.Value
              OUT_VeTHDR_b_IUMPR_HTAPTemp_Perf_Value: accessed-variable=VeTHDR_b_IUMPR_HTAPTemp_Perf.Value
              OUT_VeTHDR_b_IUMPR_PPCTIS_Perf_Value: accessed-variable=VeTHDR_b_IUMPR_PPCTIS_Perf.Value
              OUT_VeTHDR_b_IUMPR_OCCTOS_Perf_Value: accessed-variable=VeTHDR_b_IUMPR_OCCTOS_Perf.Value
              OUT_VeTHDR_b_IUMPR_LTPPTemp_Perf_Value: accessed-variable=VeTHDR_b_IUMPR_LTPPTemp_Perf.Value
              OUT_VeTHDR_b_IUMPR_LTPP2Temp_Perf_Value: accessed-variable=VeTHDR_b_IUMPR_LTPP2Temp_Perf.Value
              OUT_VeTHDR_e_FaultSts_AGS_B_Perf_Value: accessed-variable=VeTHDR_e_FaultSts_AGS_B_Perf.Value
              OUT_VeTHDR_e_FaultSts_AGS_A_Perf_Value: accessed-variable=VeTHDR_e_FaultSts_AGS_A_Perf.Value
              OUT_VeTHDR_e_FaultSts_ClntTempTooHigh_Value: accessed-variable=VeTHDR_e_FaultSts_ClntTempTooHigh.Value
              OUT_VeTHDR_e_FaultSts_ECH_TempIn_Value: accessed-variable=VeTHDR_e_FaultSts_ECH_TempIn.Value
              OUT_VeTHDR_e_FaultSts_ECH_TempOut_Value: accessed-variable=VeTHDR_e_FaultSts_ECH_TempOut.Value
              OUT_VeTHDR_e_FaultSts_CT2_SnsrPerf_Value: accessed-variable=VeTHDR_e_FaultSts_CT2_SnsrPerf.Value
              OUT_VeTHDR_e_FaultSts_CT3_SnsrPerf_Value: accessed-variable=VeTHDR_e_FaultSts_CT3_SnsrPerf.Value
              OUT_VeTHDR_e_FaultSts_ECT_Snsr4CktPerf_Value: accessed-variable=VeTHDR_e_FaultSts_ECT_Snsr4CktPerf.Value
              OUT_VeTHDR_e_FaultSts_CoolPmpATempSnsrPerf_Value: accessed-variable=VeTHDR_e_FaultSts_CoolPmpATempSnsrPerf.Value
              OUT_VeTHDR_e_FaultSts_MtrElect_CT_SnsrBPerf_Value: accessed-variable=VeTHDR_e_FaultSts_MtrElect_CT_SnsrBPerf.Value
              OUT_VeTHDR_e_FaultSts_MtrElect_CoolPmpBTempSnsrPerf_Value: accessed-variable=VeTHDR_e_FaultSts_MtrElect_CoolPmpBTempSnsrPerf.Value
              OUT_VeTHDR_e_FaultSts_MtrElect_CoolPmpATempSnsrPerf_Value: accessed-variable=VeTHDR_e_FaultSts_MtrElect_CoolPmpATempSnsrPerf.Value
              OUT_VeTHDR_e_FaultSts_CT_SnsrPerf_Value: accessed-variable=VeTHDR_e_FaultSts_CT_SnsrPerf.Value
              OUT_VeTHDR_e_FaultSts_MtrElect_CT_SnsrPerf_Value: accessed-variable=VeTHDR_e_FaultSts_MtrElect_CT_SnsrPerf.Value
              OUT_VeTHDR_e_FaultSts_AC_RefrigTempSnsr4CktPerf_Value: accessed-variable=VeTHDR_e_FaultSts_AC_RefrigTempSnsr4CktPerf.Value
              OUT_VeTHDR_e_FaultSts_AC_RefrigTempSnsr5CktPerf_Value: accessed-variable=VeTHDR_e_FaultSts_AC_RefrigTempSnsr5CktPerf.Value
              OUT_VeTHDR_e_FaultSts_AC_RefrigTempSnsrCPerf_Value: accessed-variable=VeTHDR_e_FaultSts_AC_RefrigTempSnsrCPerf.Value
        THDR_PwrOn
          data-receive-point-by-arguments:
            17 x access:
              IN_NeTHDR_Cnt_AGS2_Perf_MFOP_Rx_NeTHDR_Cnt_AGS2_Perf_MFOP: accessed-variable=NeTHDR_Cnt_AGS2_Perf_MFOP_Rx.NeTHDR_Cnt_AGS2_Perf_MFOP
              IN_NeTHDR_Cnt_AGS_Perf_MFOP_Rx_NeTHDR_Cnt_AGS_Perf_MFOP: accessed-variable=NeTHDR_Cnt_AGS_Perf_MFOP_Rx.NeTHDR_Cnt_AGS_Perf_MFOP
              IN_NeTHDR_Cnt_ECHTIS_MFOP_Rx_NeTHDR_Cnt_ECHTIS_MFOP: accessed-variable=NeTHDR_Cnt_ECHTIS_MFOP_Rx.NeTHDR_Cnt_ECHTIS_MFOP
              IN_NeTHDR_Cnt_ECH_outTmpSns_MFOP_Rx_NeTHDR_Cnt_ECH_outTmpSns_MFOP: accessed-variable=NeTHDR_Cnt_ECH_outTmpSns_MFOP_Rx.NeTHDR_Cnt_ECH_outTmpSns_MFOP
              IN_NeTHDR_Cnt_EEXV_Out_MFOP_Rx_NeTHDR_Cnt_EEXV_Out_MFOP: accessed-variable=NeTHDR_Cnt_EEXV_Out_MFOP_Rx.NeTHDR_Cnt_EEXV_Out_MFOP
              IN_NeTHDR_Cnt_HCCTIS_MFOP_Rx_NeTHDR_Cnt_HCCTIS_MFOP: accessed-variable=NeTHDR_Cnt_HCCTIS_MFOP_Rx.NeTHDR_Cnt_HCCTIS_MFOP
              IN_NeTHDR_Cnt_HCCTOS_MFOP_Rx_NeTHDR_Cnt_HCCTOS_MFOP: accessed-variable=NeTHDR_Cnt_HCCTOS_MFOP_Rx.NeTHDR_Cnt_HCCTOS_MFOP
              IN_NeTHDR_Cnt_HTAP_MFOP_Rx_NeTHDR_Cnt_HTAP_MFOP: accessed-variable=NeTHDR_Cnt_HTAP_MFOP_Rx.NeTHDR_Cnt_HTAP_MFOP
              IN_NeTHDR_Cnt_InTmpSns_MFOP_Rx_NeTHDR_Cnt_InTmpSns_MFOP: accessed-variable=NeTHDR_Cnt_InTmpSns_MFOP_Rx.NeTHDR_Cnt_InTmpSns_MFOP
              IN_NeTHDR_Cnt_LRCTOS_MFOP_Rx_NeTHDR_Cnt_LRCTOS_MFOP: accessed-variable=NeTHDR_Cnt_LRCTOS_MFOP_Rx.NeTHDR_Cnt_LRCTOS_MFOP
              IN_NeTHDR_Cnt_LTPP2_MFOP_Rx_NeTHDR_Cnt_LTPP2_MFOP: accessed-variable=NeTHDR_Cnt_LTPP2_MFOP_Rx.NeTHDR_Cnt_LTPP2_MFOP
              IN_NeTHDR_Cnt_LTPP_MFOP_Rx_NeTHDR_Cnt_LTPP_MFOP: accessed-variable=NeTHDR_Cnt_LTPP_MFOP_Rx.NeTHDR_Cnt_LTPP_MFOP
              IN_NeTHDR_Cnt_OEXV_In_MFOP_Rx_NeTHDR_Cnt_OEXV_In_MFOP: accessed-variable=NeTHDR_Cnt_OEXV_In_MFOP_Rx.NeTHDR_Cnt_OEXV_In_MFOP
              IN_NeTHDR_Cnt_OEXV_Out_MFOP_Rx_NeTHDR_Cnt_OEXV_Out_MFOP: accessed-variable=NeTHDR_Cnt_OEXV_Out_MFOP_Rx.NeTHDR_Cnt_OEXV_Out_MFOP
              IN_NeTHDR_Cnt_OOCTOS_MFOP_Rx_NeTHDR_Cnt_OOCTOS_MFOP: accessed-variable=NeTHDR_Cnt_OOCTOS_MFOP_Rx.NeTHDR_Cnt_OOCTOS_MFOP
              IN_NeTHDR_Cnt_PPCTIS_MFOP_Rx_NeTHDR_Cnt_PPCTIS_MFOP: accessed-variable=NeTHDR_Cnt_PPCTIS_MFOP_Rx.NeTHDR_Cnt_PPCTIS_MFOP
              IN_NeTHDR_Cnt_PPCTIS_OT_MSOP_Rx_NeTHDR_Cnt_PPCTIS_OT_MSOP: accessed-variable=NeTHDR_Cnt_PPCTIS_OT_MSOP_Rx.NeTHDR_Cnt_PPCTIS_OT_MSOP
          data-send-points:
            33 x access:
              OUT_VeTHDR_b_ECHTIS_FltDtct_Value: accessed-variable=VeTHDR_b_ECHTIS_FltDtct.Value
              OUT_VeTHDR_b_InTmpSns_FltDtct_Value: accessed-variable=VeTHDR_b_InTmpSns_FltDtct.Value
              OUT_VeTHDR_b_PPCTIS_FltDtct_Value: accessed-variable=VeTHDR_b_PPCTIS_FltDtct.Value
              OUT_VeTHDR_b_PPCTIS_OT_FltDtct_Value: accessed-variable=VeTHDR_b_PPCTIS_OT_FltDtct.Value
              OUT_VeTHDR_b_PPCTIS_RtnltyEnbl_Value: accessed-variable=VeTHDR_b_PPCTIS_RtnltyEnbl.Value
              OUT_VeTHDR_b_IUMPR_ECH_TempOutPerf_Value: accessed-variable=VeTHDR_b_IUMPR_ECH_TempOutPerf.Value
              OUT_VeTHDR_b_IUMPR_ECH_TempInPerf_Value: accessed-variable=VeTHDR_b_IUMPR_ECH_TempInPerf.Value
              OUT_VeTHDR_b_IUMPR_ECHTIS_Perf_Value: accessed-variable=VeTHDR_b_IUMPR_ECHTIS_Perf.Value
              OUT_VeTHDR_b_IUMPR_ECTSnsr_Perf_Value: accessed-variable=VeTHDR_b_IUMPR_ECTSnsr_Perf.Value
              OUT_VeTHDR_b_IUMPR_HTAPTemp_Perf_Value: accessed-variable=VeTHDR_b_IUMPR_HTAPTemp_Perf.Value
              OUT_VeTHDR_b_IUMPR_PPCTIS_Perf_Value: accessed-variable=VeTHDR_b_IUMPR_PPCTIS_Perf.Value
              OUT_VeTHDR_b_IUMPR_OCCTOS_Perf_Value: accessed-variable=VeTHDR_b_IUMPR_OCCTOS_Perf.Value
              OUT_VeTHDR_b_IUMPR_LTPPTemp_Perf_Value: accessed-variable=VeTHDR_b_IUMPR_LTPPTemp_Perf.Value
              OUT_VeTHDR_b_IUMPR_LTPP2Temp_Perf_Value: accessed-variable=VeTHDR_b_IUMPR_LTPP2Temp_Perf.Value
              OUT_VeTHDR_b_AGS_Perf_FltDtct_Value: accessed-variable=VeTHDR_b_AGS_Perf_FltDtct.Value
              OUT_VeTHDR_b_AGS2_Perf_FltDtct_Value: accessed-variable=VeTHDR_b_AGS2_Perf_FltDtct.Value
              OUT_VeTHDR_e_FaultSts_AGS_B_Perf_Value: accessed-variable=VeTHDR_e_FaultSts_AGS_B_Perf.Value
              OUT_VeTHDR_e_FaultSts_AGS_A_Perf_Value: accessed-variable=VeTHDR_e_FaultSts_AGS_A_Perf.Value
              OUT_VeTHDR_e_FaultSts_ClntTempTooHigh_Value: accessed-variable=VeTHDR_e_FaultSts_ClntTempTooHigh.Value
              OUT_VeTHDR_e_FaultSts_ECH_TempIn_Value: accessed-variable=VeTHDR_e_FaultSts_ECH_TempIn.Value
              OUT_VeTHDR_e_FaultSts_ECH_TempOut_Value: accessed-variable=VeTHDR_e_FaultSts_ECH_TempOut.Value
              OUT_VeTHDR_e_FaultSts_CT2_SnsrPerf_Value: accessed-variable=VeTHDR_e_FaultSts_CT2_SnsrPerf.Value
              OUT_VeTHDR_e_FaultSts_CT3_SnsrPerf_Value: accessed-variable=VeTHDR_e_FaultSts_CT3_SnsrPerf.Value
              OUT_VeTHDR_e_FaultSts_ECT_Snsr4CktPerf_Value: accessed-variable=VeTHDR_e_FaultSts_ECT_Snsr4CktPerf.Value
              OUT_VeTHDR_e_FaultSts_CoolPmpATempSnsrPerf_Value: accessed-variable=VeTHDR_e_FaultSts_CoolPmpATempSnsrPerf.Value
              OUT_VeTHDR_e_FaultSts_MtrElect_CT_SnsrBPerf_Value: accessed-variable=VeTHDR_e_FaultSts_MtrElect_CT_SnsrBPerf.Value
              OUT_VeTHDR_e_FaultSts_MtrElect_CoolPmpBTempSnsrPerf_Value: accessed-variable=VeTHDR_e_FaultSts_MtrElect_CoolPmpBTempSnsrPerf.Value
              OUT_VeTHDR_e_FaultSts_MtrElect_CoolPmpATempSnsrPerf_Value: accessed-variable=VeTHDR_e_FaultSts_MtrElect_CoolPmpATempSnsrPerf.Value
              OUT_VeTHDR_e_FaultSts_CT_SnsrPerf_Value: accessed-variable=VeTHDR_e_FaultSts_CT_SnsrPerf.Value
              OUT_VeTHDR_e_FaultSts_MtrElect_CT_SnsrPerf_Value: accessed-variable=VeTHDR_e_FaultSts_MtrElect_CT_SnsrPerf.Value
              OUT_VeTHDR_e_FaultSts_AC_RefrigTempSnsr4CktPerf_Value: accessed-variable=VeTHDR_e_FaultSts_AC_RefrigTempSnsr4CktPerf.Value
              OUT_VeTHDR_e_FaultSts_AC_RefrigTempSnsr5CktPerf_Value: accessed-variable=VeTHDR_e_FaultSts_AC_RefrigTempSnsr5CktPerf.Value
              OUT_VeTHDR_e_FaultSts_AC_RefrigTempSnsrCPerf_Value: accessed-variable=VeTHDR_e_FaultSts_AC_RefrigTempSnsrCPerf.Value
        THDR_PwrOff
          data-send-points:
            17 x access:
              OUT_NeTHDR_Cnt_AGS2_Perf_MFOP_NeTHDR_Cnt_AGS2_Perf_MFOP: accessed-variable=NeTHDR_Cnt_AGS2_Perf_MFOP.NeTHDR_Cnt_AGS2_Perf_MFOP
              OUT_NeTHDR_Cnt_AGS_Perf_MFOP_NeTHDR_Cnt_AGS_Perf_MFOP: accessed-variable=NeTHDR_Cnt_AGS_Perf_MFOP.NeTHDR_Cnt_AGS_Perf_MFOP
              OUT_NeTHDR_Cnt_ECHTIS_MFOP_NeTHDR_Cnt_ECHTIS_MFOP: accessed-variable=NeTHDR_Cnt_ECHTIS_MFOP.NeTHDR_Cnt_ECHTIS_MFOP
              OUT_NeTHDR_Cnt_ECH_outTmpSns_MFOP_NeTHDR_Cnt_ECH_outTmpSns_MFOP: accessed-variable=NeTHDR_Cnt_ECH_outTmpSns_MFOP.NeTHDR_Cnt_ECH_outTmpSns_MFOP
              OUT_NeTHDR_Cnt_HCCTIS_MFOP_NeTHDR_Cnt_HCCTIS_MFOP: accessed-variable=NeTHDR_Cnt_HCCTIS_MFOP.NeTHDR_Cnt_HCCTIS_MFOP
              OUT_NeTHDR_Cnt_HCCTOS_MFOP_NeTHDR_Cnt_HCCTOS_MFOP: accessed-variable=NeTHDR_Cnt_HCCTOS_MFOP.NeTHDR_Cnt_HCCTOS_MFOP
              OUT_NeTHDR_Cnt_HTAP_MFOP_NeTHDR_Cnt_HTAP_MFOP: accessed-variable=NeTHDR_Cnt_HTAP_MFOP.NeTHDR_Cnt_HTAP_MFOP
              OUT_NeTHDR_Cnt_InTmpSns_MFOP_NeTHDR_Cnt_InTmpSns_MFOP: accessed-variable=NeTHDR_Cnt_InTmpSns_MFOP.NeTHDR_Cnt_InTmpSns_MFOP
              OUT_NeTHDR_Cnt_LRCTOS_MFOP_NeTHDR_Cnt_LRCTOS_MFOP: accessed-variable=NeTHDR_Cnt_LRCTOS_MFOP.NeTHDR_Cnt_LRCTOS_MFOP
              OUT_NeTHDR_Cnt_LTPP2_MFOP_NeTHDR_Cnt_LTPP2_MFOP: accessed-variable=NeTHDR_Cnt_LTPP2_MFOP.NeTHDR_Cnt_LTPP2_MFOP
              OUT_NeTHDR_Cnt_LTPP_MFOP_NeTHDR_Cnt_LTPP_MFOP: accessed-variable=NeTHDR_Cnt_LTPP_MFOP.NeTHDR_Cnt_LTPP_MFOP
              OUT_NeTHDR_Cnt_OOCTOS_MFOP_NeTHDR_Cnt_OOCTOS_MFOP: accessed-variable=NeTHDR_Cnt_OOCTOS_MFOP.NeTHDR_Cnt_OOCTOS_MFOP
              OUT_NeTHDR_Cnt_PPCTIS_MFOP_NeTHDR_Cnt_PPCTIS_MFOP: accessed-variable=NeTHDR_Cnt_PPCTIS_MFOP.NeTHDR_Cnt_PPCTIS_MFOP
              OUT_NeTHDR_Cnt_PPCTIS_OT_MSOP_NeTHDR_Cnt_PPCTIS_OT_MSOP: accessed-variable=NeTHDR_Cnt_PPCTIS_OT_MSOP.NeTHDR_Cnt_PPCTIS_OT_MSOP
              OUT_NeTHDR_Cnt_OEXV_Out_MFOP_NeTHDR_Cnt_OEXV_Out_MFOP: accessed-variable=NeTHDR_Cnt_OEXV_Out_MFOP.NeTHDR_Cnt_OEXV_Out_MFOP
              OUT_NeTHDR_Cnt_OEXV_In_MFOP_NeTHDR_Cnt_OEXV_In_MFOP: accessed-variable=NeTHDR_Cnt_OEXV_In_MFOP.NeTHDR_Cnt_OEXV_In_MFOP
              OUT_NeTHDR_Cnt_EEXV_Out_MFOP_NeTHDR_Cnt_EEXV_Out_MFOP: accessed-variable=NeTHDR_Cnt_EEXV_Out_MFOP.NeTHDR_Cnt_EEXV_Out_MFOP
      19 x variation point proxy, all with category=CONDITION:
        Variant_THDR_1: condition-access=0
        Variant_THDR_10: condition-access=1
        Variant_THDR_11: condition-access=0
        Variant_THDR_12: condition-access=1
        Variant_THDR_13: condition-access=1
        Variant_THDR_14: condition-access=0
        Variant_THDR_19: condition-access=1
        Variant_THDR_2: condition-access=0
        Variant_THDR_20: condition-access=0
        Variant_THDR_21: condition-access=0
        Variant_THDR_22: condition-access=1
        Variant_THDR_23: condition-access=0
        Variant_THDR_3: condition-access=0
        Variant_THDR_4: condition-access=0
        Variant_THDR_5: condition-access=1
        Variant_THDR_6: condition-access=0
        Variant_THDR_7: condition-access=0
        Variant_THDR_8: condition-access=1
        Variant_THDR_9: condition-access=1
